VERSION ""

NS_ :

BS_:

BU_: PDM INV U2C VCU BMS Charger Can_Isolator CAN_T_Repeater CAN_Isolator

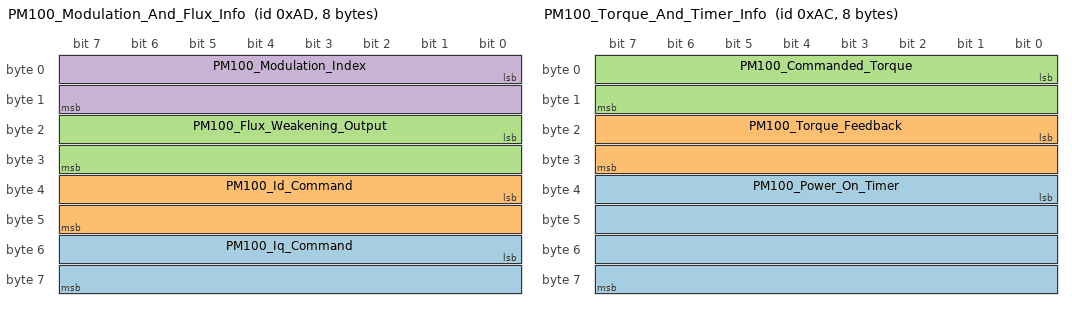
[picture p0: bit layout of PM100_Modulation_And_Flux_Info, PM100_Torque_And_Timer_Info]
BO_ 173 PM100_Modulation_And_Flux_Info: 8 INV
 SG_ PM100_Iq_Command : 48|16@1- (0.1,0) [-3276.8|3276.7] "A" Vector__XXX
 SG_ PM100_Id_Command : 32|16@1- (0.1,0) [-3276.8|3276.7] "A" Vector__XXX
 SG_ PM100_Flux_Weakening_Output : 16|16@1- (0.1,0) [-3276.8|3276.7] "A" Vector__XXX
 SG_ PM100_Modulation_Index : 0|16@1- (0.0001,0) [-3.2768|3.2767] "" Vector__XXX

BO_ 172 PM100_Torque_And_Timer_Info: 8 INV
 SG_ PM100_Power_On_Timer : 32|32@1+ (0.003,0) [0|12884800] "s" Vector__XXX
 SG_ PM100_Torque_Feedback : 16|16@1- (0.1,0) [-3276.8|3276.7] "Nm" Vector__XXX
 SG_ PM100_Commanded_Torque : 0|16@1- (0.1,0) [-3276.8|3276.7] "Nm" Vector__XXX

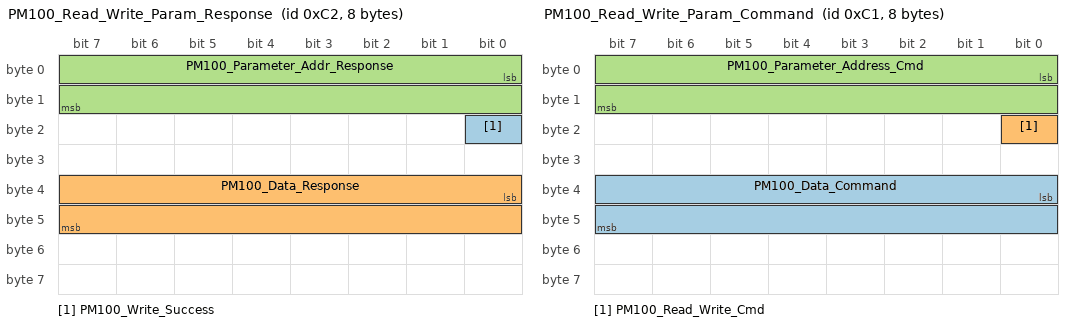
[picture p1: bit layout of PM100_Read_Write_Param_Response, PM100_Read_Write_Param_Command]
BO_ 194 PM100_Read_Write_Param_Response: 8 INV
 SG_ PM100_Write_Success : 16|1@1+ (1,0) [0|1] "" Vector__XXX
 SG_ PM100_Data_Response : 32|16@1- (1,0) [-32768|32767] "" Vector__XXX
 SG_ PM100_Parameter_Addr_Response : 0|16@1+ (1,0) [0|65535] "" Vector__XXX

BO_ 193 PM100_Read_Write_Param_Command: 8 VCU
 SG_ PM100_Data_Command : 32|16@1- (1,0) [-32768|32767] "" Vector__XXX
 SG_ PM100_Read_Write_Cmd : 16|1@1+ (1,0) [0|1] "" Vector__XXX
 SG_ PM100_Parameter_Address_Cmd : 0|16@1+ (1,0) [0|65535] "" Vector__XXX

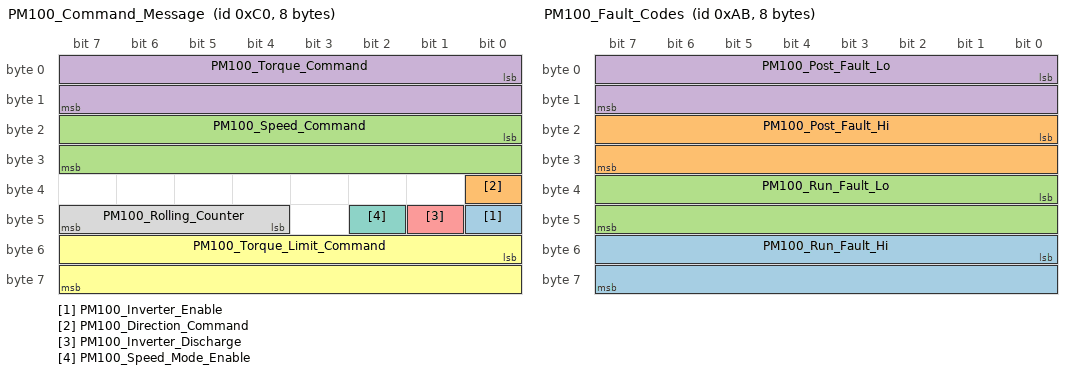
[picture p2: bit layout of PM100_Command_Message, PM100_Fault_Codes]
BO_ 192 PM100_Command_Message: 8 VCU
 SG_ PM100_Inverter_Enable : 40|1@1+ (1,0) [0|1] "Bit" Vector__XXX
 SG_ PM100_Direction_Command : 32|1@1+ (1,0) [0|1] "Bit" Vector__XXX
 SG_ PM100_Speed_Command : 16|16@1- (1,0) [-32768|32767] "rpm" Vector__XXX
 SG_ PM100_Torque_Command : 0|16@1- (0.1,0) [-3276.8|3276.7] "Nm" Vector__XXX
 SG_ PM100_Inverter_Discharge : 41|1@1+ (1,0) [0|1] "Bit" Vector__XXX
 SG_ PM100_Torque_Limit_Command : 48|16@1- (0.1,0) [-3276.8|3276.7] "Nm" Vector__XXX
 SG_ PM100_Speed_Mode_Enable : 42|1@1+ (1,0) [0|1] "Bit" Vector__XXX
 SG_ PM100_Rolling_Counter : 44|4@1+ (1,0) [0|15] "Bits" Vector__XXX

BO_ 171 PM100_Fault_Codes: 8 INV
 SG_ PM100_Run_Fault_Hi : 48|16@1+ (1,0) [0|65535] "" Vector__XXX
 SG_ PM100_Post_Fault_Hi : 16|16@1+ (1,0) [0|65535] "" Vector__XXX
 SG_ PM100_Run_Fault_Lo : 32|16@1+ (1,0) [0|65535] "" Vector__XXX
 SG_ PM100_Post_Fault_Lo : 0|16@1+ (1,0) [0|65535] "" Vector__XXX

BO_ 170 PM100_Internal_States: 8 INV
 SG_ PM100_Direction_Command : 56|1@1+ (1,0) [0|1] "" Vector__XXX
 SG_ PM100_Inverter_Enable_State : 48|1@1+ (1,0) [0|1] "" Vector__XXX
 SG_ PM100_Relay_3_Status : 26|1@1+ (1,0) [0|1] "" Vector__XXX
 SG_ PM100_Relay_4_Status : 27|1@1+ (1,0) [0|1] "" Vector__XXX
 SG_ PM100_Relay_2_Status : 25|1@1+ (1,0) [0|1] "" Vector__XXX
 SG_ PM100_Inverter_Run_Mode : 32|1@1+ (1,0) [0|1] "" Vector__XXX
 SG_ PM100_Inverter_Command_Mode : 40|1@1+ (1,0) [0|1] "" Vector__XXX
 SG_ PM100_Relay_1_Status : 24|1@1+ (1,0) [0|1] "" Vector__XXX
 SG_ PM100_Inverter_State : 16|8@1+ (1,0) [0|255] "" Vector__XXX
 SG_ PM100_VSM_State : 0|8@1+ (1,0) [0|15] "" Vector__XXX
 SG_ PM100_Inverter_Enable_Lockout : 55|1@1+ (1,0) [0|1] "" Vector__XXX
 SG_ PM100_Inverter_Discharge_State : 37|3@1+ (1,0) [0|7] "" Vector__XXX
 SG_ PM100_Relay_5_Status : 28|1@1+ (1,0) [0|1] "" Vector__XXX
 SG_ PM100_Relay_6_Status : 29|1@1+ (1,0) [0|1] "" Vector__XXX
 SG_ PM100_BMS_Active : 57|1@1+ (1,0) [0|1] "" Vector__XXX
 SG_ PM100_BMS_Torque_Limiting : 58|1@1+ (1,0) [0|1] "" Vector__XXX
 SG_ PM100_Max_Speed_Limiting : 59|1@1+ (1,0) [0|1] "" Vector__XXX
 SG_ PM100_Low_Speed_Limiting : 61|1@1+ (1,0) [0|1] "" Vector__XXX
 SG_ PM100_Rolling_Counter : 44|4@1+ (1,0) [0|15] "" Vector__XXX
 SG_ PM100_PWM_Frequency : 8|8@1+ (1,0) [0|255] "kHz" Vector__XXX
 SG_ PM100_Start_Mode_Active : 54|1@1+ (1,0) [0|1] "" Vector__XXX

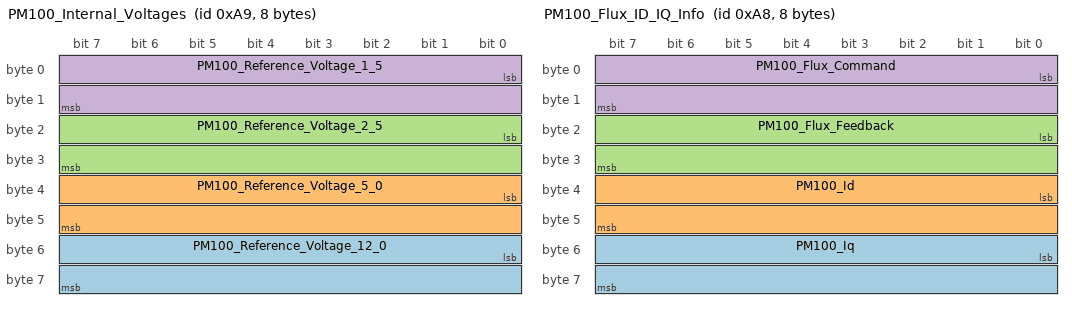
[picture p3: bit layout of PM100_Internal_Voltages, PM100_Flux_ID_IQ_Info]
BO_ 169 PM100_Internal_Voltages: 8 INV
 SG_ PM100_Reference_Voltage_12_0 : 48|16@1- (0.01,0) [-327.68|327.67] "V" Vector__XXX
 SG_ PM100_Reference_Voltage_5_0 : 32|16@1- (0.01,0) [-327.68|327.67] "V" Vector__XXX
 SG_ PM100_Reference_Voltage_2_5 : 16|16@1- (0.01,0) [-327.68|327.67] "V" Vector__XXX
 SG_ PM100_Reference_Voltage_1_5 : 0|16@1- (0.01,0) [-327.68|327.67] "V" Vector__XXX

BO_ 168 PM100_Flux_ID_IQ_Info: 8 INV
 SG_ PM100_Iq : 48|16@1- (0.1,0) [-3276.8|3276.7] "A" Vector__XXX
 SG_ PM100_Id : 32|16@1- (0.1,0) [-3276.8|3276.7] "A" Vector__XXX
 SG_ PM100_Flux_Feedback : 16|16@1- (0.001,0) [-32.768|32.767] "Wb" Vector__XXX
 SG_ PM100_Flux_Command : 0|16@1- (0.001,0) [-32.768|32.767] "Wb" Vector__XXX

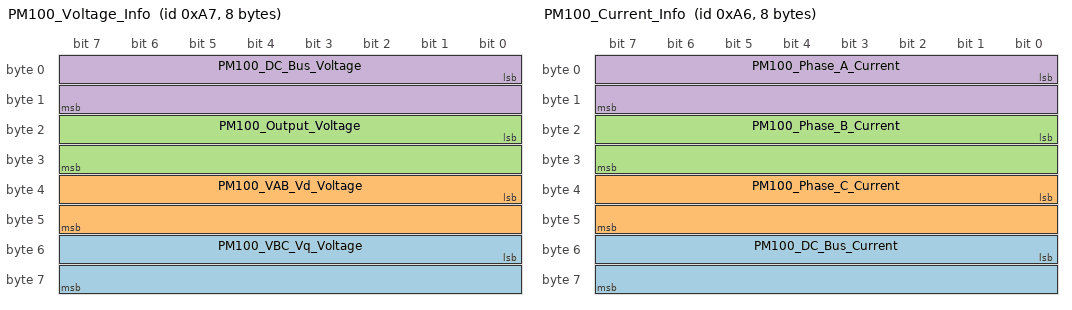
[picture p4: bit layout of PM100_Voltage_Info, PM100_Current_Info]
BO_ 167 PM100_Voltage_Info: 8 INV
 SG_ PM100_VBC_Vq_Voltage : 48|16@1- (0.1,0) [-3276.8|3276.7] "V" Vector__XXX
 SG_ PM100_VAB_Vd_Voltage : 32|16@1- (0.1,0) [-3276.8|3276.7] "V" Vector__XXX
 SG_ PM100_Output_Voltage : 16|16@1- (0.1,0) [-3276.8|3276.7] "V" Vector__XXX
 SG_ PM100_DC_Bus_Voltage : 0|16@1- (0.1,0) [-3276.8|3276.7] "V" Vector__XXX

BO_ 166 PM100_Current_Info: 8 INV
 SG_ PM100_DC_Bus_Current : 48|16@1- (0.1,0) [-3276.8|3276.7] "A" Vector__XXX
 SG_ PM100_Phase_C_Current : 32|16@1- (0.1,0) [-3276.8|3276.7] "A" Vector__XXX
 SG_ PM100_Phase_B_Current : 16|16@1- (0.1,0) [-3276.8|3276.7] "A" Vector__XXX
 SG_ PM100_Phase_A_Current : 0|16@1- (0.1,0) [-3276.8|3276.7] "A" Vector__XXX

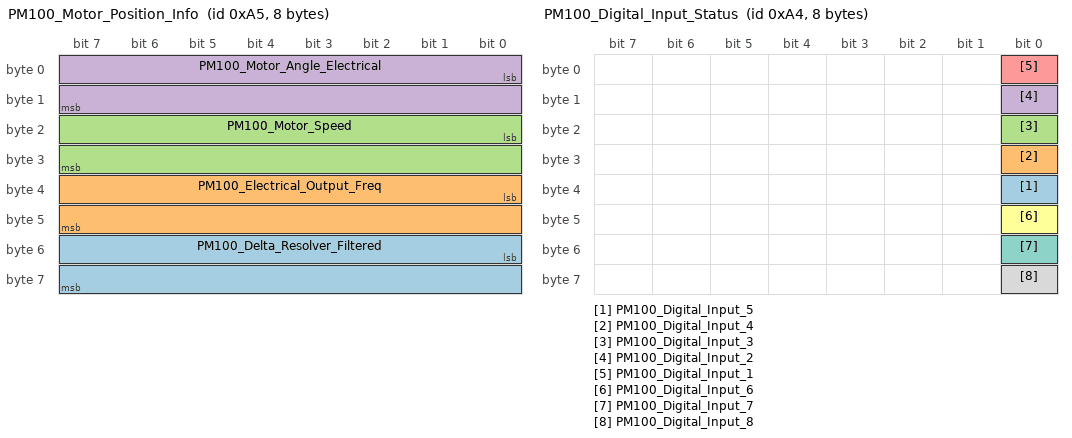
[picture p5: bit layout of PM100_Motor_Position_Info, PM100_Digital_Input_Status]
BO_ 165 PM100_Motor_Position_Info: 8 INV
 SG_ PM100_Delta_Resolver_Filtered : 48|16@1- (0.1,0) [-3276.8|3276.7] "deg" Vector__XXX
 SG_ PM100_Electrical_Output_Freq : 32|16@1- (0.1,0) [-3276.8|3276.7] "hz" Vector__XXX
 SG_ PM100_Motor_Speed : 16|16@1- (1,0) [-32768|32767] "rpm" Vector__XXX
 SG_ PM100_Motor_Angle_Electrical : 0|16@1+ (0.1,0) [0|6553.5] "deg" Vector__XXX

BO_ 164 PM100_Digital_Input_Status: 8 INV
 SG_ PM100_Digital_Input_5 : 32|1@1+ (1,0) [0|1] "boolean" Vector__XXX
 SG_ PM100_Digital_Input_4 : 24|1@1+ (1,0) [0|1] "boolean" Vector__XXX
 SG_ PM100_Digital_Input_3 : 16|1@1+ (1,0) [0|1] "boolean" Vector__XXX
 SG_ PM100_Digital_Input_2 : 8|1@1+ (1,0) [0|1] "boolean" Vector__XXX
 SG_ PM100_Digital_Input_1 : 0|1@1+ (1,0) [0|1] "boolean" Vector__XXX
 SG_ PM100_Digital_Input_6 : 40|1@1+ (1,0) [0|1] "boolean" Vector__XXX
 SG_ PM100_Digital_Input_7 : 48|1@1+ (1,0) [0|1] "boolean" Vector__XXX
 SG_ PM100_Digital_Input_8 : 56|1@1+ (1,0) [0|1] "boolean" Vector__XXX

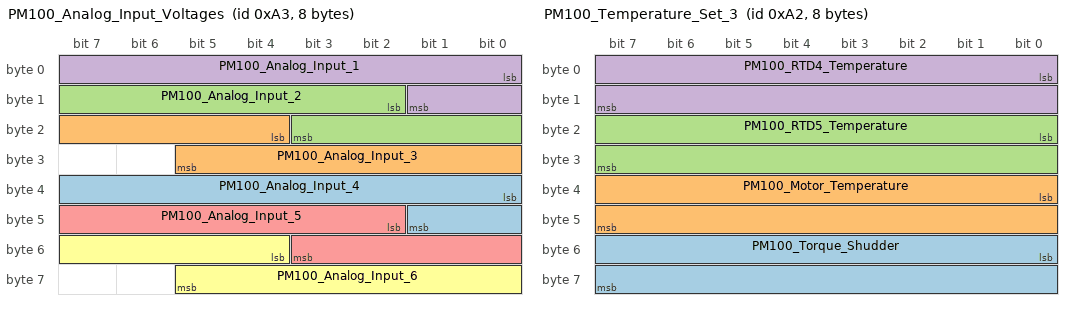
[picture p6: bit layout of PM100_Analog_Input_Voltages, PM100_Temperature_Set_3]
BO_ 163 PM100_Analog_Input_Voltages: 8 INV
 SG_ PM100_Analog_Input_4 : 32|10@1+ (0.01,0) [0|10.23] "V" Vector__XXX
 SG_ PM100_Analog_Input_3 : 20|10@1+ (0.01,0) [0|10.23] "V" Vector__XXX
 SG_ PM100_Analog_Input_2 : 10|10@1+ (0.01,0) [0|10.23] "V" Vector__XXX
 SG_ PM100_Analog_Input_1 : 0|10@1+ (0.01,0) [0|10.23] "V" Vector__XXX
 SG_ PM100_Analog_Input_5 : 42|10@1+ (0.01,0) [0|10.23] "V" Vector__XXX
 SG_ PM100_Analog_Input_6 : 52|10@1+ (0.01,0) [0|10.23] "V" Vector__XXX

BO_ 162 PM100_Temperature_Set_3: 8 INV
 SG_ PM100_Torque_Shudder : 48|16@1- (0.1,0) [-3276.8|3276.7] "Nm" Vector__XXX
 SG_ PM100_Motor_Temperature : 32|16@1- (0.1,0) [-3276.8|3276.7] "degC" Vector__XXX
 SG_ PM100_RTD5_Temperature : 16|16@1- (0.1,0) [-3276.8|3276.7] "degC" Vector__XXX
 SG_ PM100_RTD4_Temperature : 0|16@1- (0.1,0) [-3276.8|3276.7] "degC" Vector__XXX

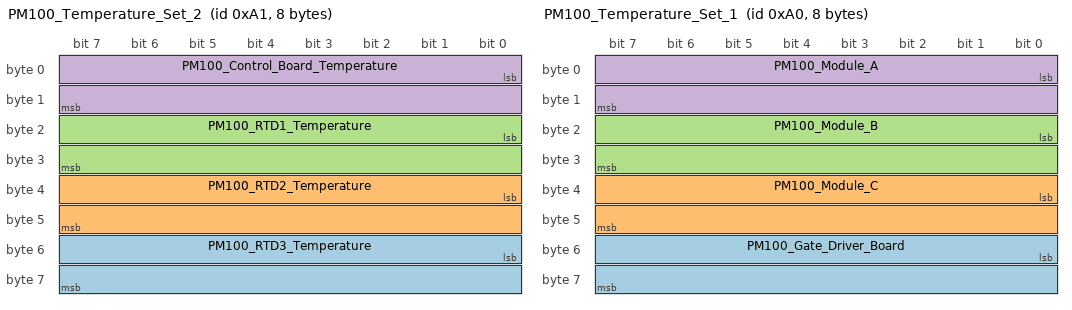
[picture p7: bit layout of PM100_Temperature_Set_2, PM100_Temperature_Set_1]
BO_ 161 PM100_Temperature_Set_2: 8 INV
 SG_ PM100_RTD3_Temperature : 48|16@1- (0.1,0) [-3276.8|3276.7] "degC" Vector__XXX
 SG_ PM100_RTD2_Temperature : 32|16@1- (0.1,0) [-3276.8|3276.7] "degC" Vector__XXX
 SG_ PM100_RTD1_Temperature : 16|16@1- (0.1,0) [-3276.8|3276.7] "degC" Vector__XXX
 SG_ PM100_Control_Board_Temperature : 0|16@1- (0.1,0) [-3276.8|3276.7] "degC" Vector__XXX

BO_ 160 PM100_Temperature_Set_1: 8 INV
 SG_ PM100_Gate_Driver_Board : 48|16@1- (0.1,0) [-3276.8|3276.7] "degC" Vector__XXX
 SG_ PM100_Module_C : 32|16@1- (0.1,0) [-3276.8|3276.7] "degC" Vector__XXX
 SG_ PM100_Module_B : 16|16@1- (0.1,0) [-3276.8|3276.7] "degC" Vector__XXX
 SG_ PM100_Module_A : 0|16@1- (0.1,0) [-3276.8|3276.7] "degC" Vector__XXX

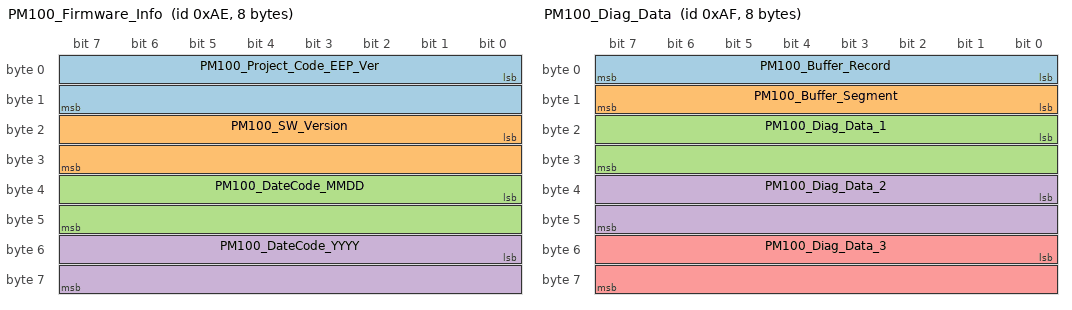
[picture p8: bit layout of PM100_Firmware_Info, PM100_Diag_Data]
BO_ 174 PM100_Firmware_Info: 8 INV
 SG_ PM100_Project_Code_EEP_Ver : 0|16@1+ (1,0) [0|65535] "" Vector__XXX
 SG_ PM100_SW_Version : 16|16@1+ (1,0) [0|65535] "" Vector__XXX
 SG_ PM100_DateCode_MMDD : 32|16@1+ (1,0) [0|65535] "" Vector__XXX
 SG_ PM100_DateCode_YYYY : 48|16@1+ (1,0) [0|65535] "" Vector__XXX

BO_ 175 PM100_Diag_Data: 8 INV
 SG_ PM100_Buffer_Record : 0|8@1+ (1,0) [0|255] "" Vector__XXX
 SG_ PM100_Buffer_Segment : 8|8@1+ (1,0) [0|5] "" Vector__XXX
 SG_ PM100_Diag_Data_1 : 16|16@1- (1,0) [-32768|32767] "" Vector__XXX
 SG_ PM100_Diag_Data_2 : 32|16@1- (1,0) [-32768|32767] "" Vector__XXX
 SG_ PM100_Diag_Data_3 : 48|16@1- (1,0) [-32768|32767] "" Vector__XXX

BO_ 471 U2C_Command_Txd: 8 INV
 SG_ PM100_ID_Byte : 0|8@1+ (1,0) [0|255] "" Vector__XXX
 SG_ PM100_Setpoint_Calc : 8|8@1+ (1,0) [0|255] "" Vector__XXX

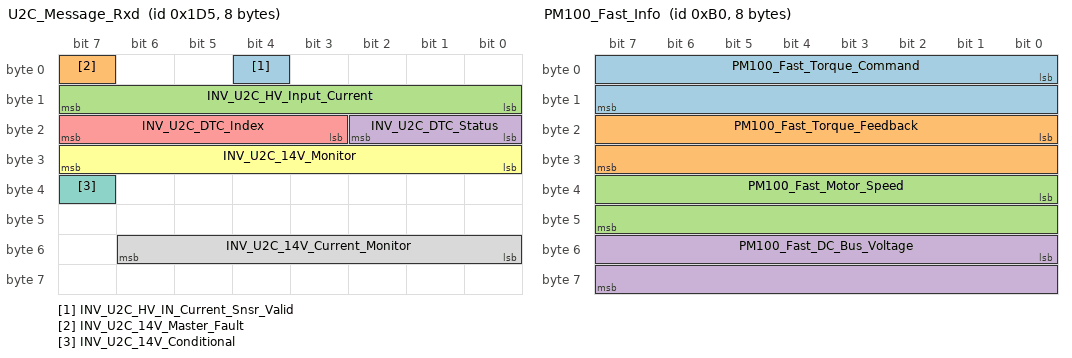
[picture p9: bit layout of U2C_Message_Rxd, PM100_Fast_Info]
BO_ 469 U2C_Message_Rxd: 8 U2C
 SG_ INV_U2C_HV_IN_Current_Snsr_Valid : 4|1@1+ (1,0) [0|1] "" Vector__XXX
 SG_ INV_U2C_14V_Master_Fault : 7|1@1+ (1,0) [0|1] "" Vector__XXX
 SG_ INV_U2C_HV_Input_Current : 8|8@1+ (1,0) [0|255] "" Vector__XXX
 SG_ INV_U2C_DTC_Status : 16|3@1+ (1,0) [0|7] "" Vector__XXX
 SG_ INV_U2C_DTC_Index : 19|5@1+ (1,0) [0|31] "" Vector__XXX
 SG_ INV_U2C_14V_Monitor : 24|8@1+ (1,0) [0|255] "" Vector__XXX
 SG_ INV_U2C_14V_Conditional : 39|1@1+ (1,0) [0|1] "" Vector__XXX
 SG_ INV_U2C_14V_Current_Monitor : 48|7@1+ (1,0) [0|127] "" Vector__XXX

BO_ 176 PM100_Fast_Info: 8 INV
 SG_ PM100_Fast_Torque_Command : 0|16@1- (0.1,0) [-3276.8|3276.7] "Nm" Vector__XXX
 SG_ PM100_Fast_Torque_Feedback : 16|16@1- (0.1,0) [-3276.8|3276.7] "Nm" Vector__XXX
 SG_ PM100_Fast_Motor_Speed : 32|16@1- (1,0) [-32768|32767] "rpm" Vector__XXX
 SG_ PM100_Fast_DC_Bus_Voltage : 48|16@1- (0.1,0) [-3276.8|3276.7] "V" Vector__XXX

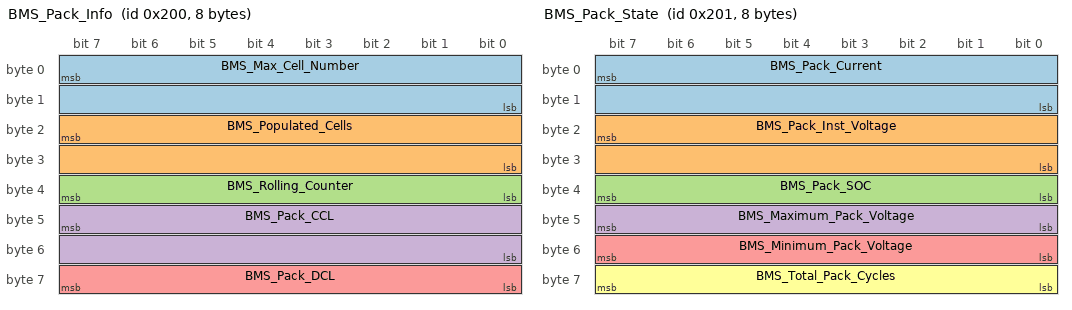
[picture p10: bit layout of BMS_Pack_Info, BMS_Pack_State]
BO_ 512 BMS_Pack_Info: 8 BMS
 SG_ BMS_Max_Cell_Number : 7|16@0+ (1,0) [0|0] "Num" Vector__XXX
 SG_ BMS_Populated_Cells : 23|16@0+ (1,0) [0|0] "Num" Vector__XXX
 SG_ BMS_Rolling_Counter : 39|8@0+ (1,0) [0|0] "Num" Vector__XXX
 SG_ BMS_Pack_CCL : 47|16@0+ (1,0) [0|0] "Amps" Vector__XXX
 SG_ BMS_Pack_DCL : 63|8@0+ (1,1720) [0|0] "Amps" Vector__XXX

BO_ 513 BMS_Pack_State: 8 BMS
 SG_ BMS_Pack_Current : 7|16@0- (0.1,0) [0|0] "Amps" Vector__XXX
 SG_ BMS_Pack_Inst_Voltage : 23|16@0+ (0.1,0) [0|0] "Volts" Vector__XXX
 SG_ BMS_Pack_SOC : 39|8@0+ (0.5,0) [0|0] "Percent" Vector__XXX
 SG_ BMS_Maximum_Pack_Voltage : 47|8@0+ (0.1,0) [0|0] "Volts" Vector__XXX
 SG_ BMS_Minimum_Pack_Voltage : 55|8@0+ (0.1,0) [0|0] "Volts" Vector__XXX
 SG_ BMS_Total_Pack_Cycles : 63|8@0+ (1,1721) [0|0] "Num" Vector__XXX

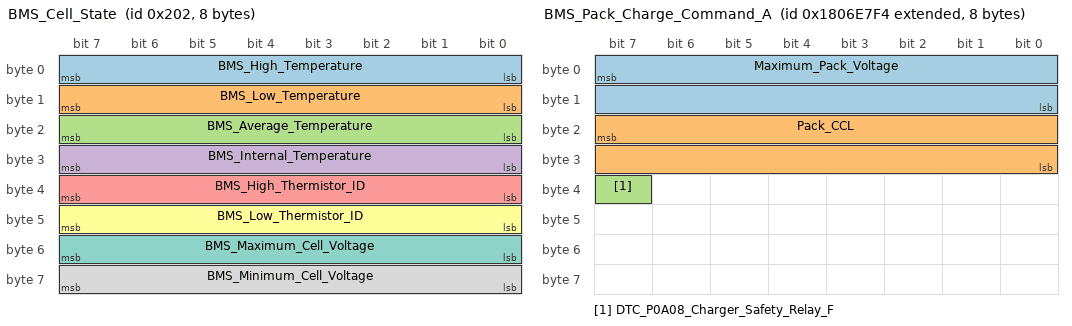
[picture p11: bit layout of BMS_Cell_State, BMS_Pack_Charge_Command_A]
BO_ 514 BMS_Cell_State: 8 BMS
 SG_ BMS_High_Temperature : 7|8@0+ (1,0) [0|0] "Celsius" Vector__XXX
 SG_ BMS_Low_Temperature : 15|8@0+ (1,0) [0|0] "Celsius" Vector__XXX
 SG_ BMS_Average_Temperature : 23|8@0+ (1,0) [0|0] "Celsius" Vector__XXX
 SG_ BMS_Internal_Temperature : 31|8@0+ (1,0) [0|0] "Celsius" Vector__XXX
 SG_ BMS_High_Thermistor_ID : 39|8@0+ (1,0) [0|0] "ID" Vector__XXX
 SG_ BMS_Low_Thermistor_ID : 47|8@0+ (1,0) [0|0] "ID" Vector__XXX
 SG_ BMS_Maximum_Cell_Voltage : 55|8@0+ (0.0001,0) [0|0] "Volts" Vector__XXX
 SG_ BMS_Minimum_Cell_Voltage : 63|8@0+ (0.0001,0) [0|0] "Volts" Vector__XXX

BO_ 515 BMS_Status: 7 BMS
 SG_ BMS_High_Cell_Voltage_ID : 0|8@1+ (1,0) [0|0] "ID" Vector__XXX
 SG_ BMS_Low_Cell_Voltage_ID : 8|8@1+ (1,0) [0|0] "ID" Vector__XXX
 SG_ BMS_Discharge_Relay : 16|1@1+ (1,0) [0|1] "" Vector__XXX
 SG_ BMS_Charge_Relay : 17|1@1+ (1,0) [0|1] "" Vector__XXX
 SG_ BMS_Charger_Safety : 18|1@1+ (1,0) [0|1] "" Vector__XXX
 SG_ BMS_Charge_Interlock : 19|1@1+ (1,0) [0|1] "" Vector__XXX
 SG_ BMS_Balancing_Active : 20|1@1+ (1,0) [0|1] "" Vector__XXX
 SG_ BMS_FAULT_Int_Cell_Comms : 24|1@1+ (1,0) [0|1] "" Vector__XXX
 SG_ BMS_FAULT_Cell_Bal_Stuck_Off : 25|1@1+ (1,0) [0|1] "" Vector__XXX
 SG_ BMS_FAULT_Weak_Cell : 26|1@1+ (1,0) [0|1] "" Vector__XXX
 SG_ BMS_FAULT_Low_Cell_Voltage : 27|1@1+ (1,0) [0|1] "" Vector__XXX
 SG_ BMS_FAULT_Cell_Open_Wiring : 28|1@1+ (1,0) [0|1] "" Vector__XXX
 SG_ BMS_FAULT_Current_Sensor : 29|1@1+ (1,0) [0|1] "" Vector__XXX
 SG_ BMS_FAULT_Cell_Voltage_Over_5V : 30|1@1+ (1,0) [0|1] "" Vector__XXX
 SG_ BMS_FAULT_Cell_Bank : 31|1@1+ (1,0) [0|1] "" Vector__XXX
 SG_ BMS_FAULT_Weak_Pack : 32|1@1+ (1,0) [0|1] "" Vector__XXX
 SG_ BMS_FAULT_Fan_Monitor : 33|1@1+ (1,0) [0|1] "" Vector__XXX
 SG_ BMS_FAULT_Thermistor : 34|1@1+ (1,0) [0|1] "" Vector__XXX
 SG_ BMS_FAULT_CAN_Communication : 35|1@1+ (1,0) [0|1] "" Vector__XXX
 SG_ BMS_FAULT_Redundant_Power_Supply : 36|1@1+ (1,0) [0|1] "" Vector__XXX
 SG_ BMS_FAULT_High_Voltage_Isolation : 37|1@1+ (1,0) [0|1] "" Vector__XXX
 SG_ BMS_FAULT_Invld_Input_Sply_Volt : 38|1@1+ (1,0) [0|1] "" Vector__XXX
 SG_ BMS_FAULT_ChargeEnable_Relay : 39|1@1+ (1,0) [0|1] "" Vector__XXX
 SG_ BMS_FAULT_DischargeEnable_Relay : 40|1@1+ (1,0) [0|1] "" Vector__XXX
 SG_ BMS_FAULT_Charger_Safety_Relay : 41|1@1+ (1,0) [0|1] "" Vector__XXX
 SG_ BMS_FAULT_Internal_Hardware : 42|1@1+ (1,0) [0|1] "" Vector__XXX
 SG_ BMS_FAULT_Internal_Temp : 43|1@1+ (1,0) [0|1] "" Vector__XXX
 SG_ BMS_FAULT_Internal_Logic : 44|1@1+ (1,0) [0|1] "" Vector__XXX
 SG_ BMS_FAULT_Hi_Cell_Voltage_High : 45|1@1+ (1,0) [0|1] "" Vector__XXX
 SG_ BMS_FAULT_Lo_Cell_Voltage_Low : 46|1@1+ (1,0) [0|1] "" Vector__XXX
 SG_ BMS_FAULT_Pack_Too_Hot : 47|1@1+ (1,0) [0|1] "" Vector__XXX
 SG_ BMS_FAULT_Hi_Volt_Intlck_Signal : 48|1@1+ (1,0) [0|1] "" Vector__XXX
 SG_ BMS_FAULT_Prchrg_Malfunction : 49|1@1+ (1,0) [0|1] "" Vector__XXX
 SG_ BMS_FAULT_Abnormal_SoC_Behavior : 50|1@1+ (1,0) [0|1] "" Vector__XXX

BO_ 528 BMS_Heartbeat: 8 Can_Isolator

BO_ 2550589428 BMS_Pack_Charge_Command_A: 8 BMS
 SG_ Maximum_Pack_Voltage : 7|16@0+ (0.1,0) [0|0] "Volts"  Charger
 SG_ Pack_CCL : 23|16@0+ (0.1,0) [0|0] "Amps"  Charger
 SG_ DTC_P0A08_Charger_Safety_Relay_F : 39|1@1+ (1,0) [0|1] ""  Charger

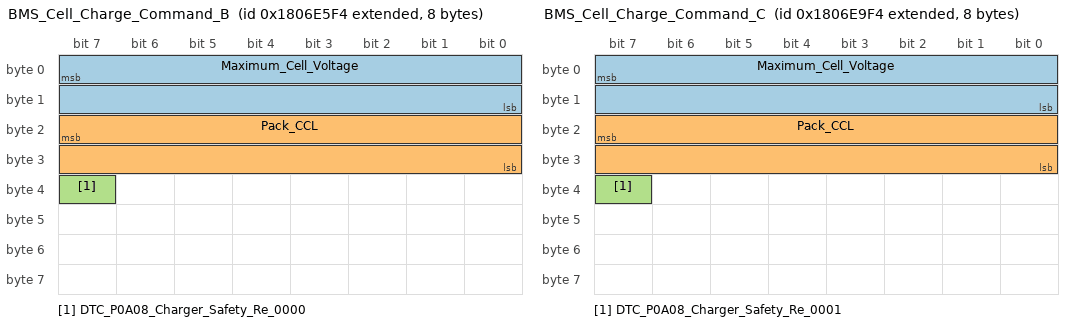
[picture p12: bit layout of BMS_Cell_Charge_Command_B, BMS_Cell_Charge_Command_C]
BO_ 2550588916 BMS_Cell_Charge_Command_B: 8 BMS
 SG_ Maximum_Cell_Voltage : 7|16@0+ (0.00104166666666667,0) [0|0] "Volts"  Charger
 SG_ Pack_CCL : 23|16@0+ (0.1,0) [0|0] "Amps"  Charger
 SG_ DTC_P0A08_Charger_Safety_Re_0000 : 39|1@1+ (1,0) [0|1] ""  Charger

BO_ 2550589940 BMS_Cell_Charge_Command_C: 8 BMS
 SG_ Maximum_Cell_Voltage : 7|16@0+ (0.00104166666666667,0) [0|0] "Volts"  Charger
 SG_ Pack_CCL : 23|16@0+ (0.1,0) [0|0] "Amps"  Charger
 SG_ DTC_P0A08_Charger_Safety_Re_0001 : 39|1@1+ (1,0) [0|1] ""  Charger

BO_ 118 BMS_Fast_Thermistor_Broadcast: 4 BMS
 SG_ BMS_Fast_Thermistor_ID M : 0|8@1+ (1,0) [0|255] "ID" Vector__XXX
 SG_ BMS_Fast_Temp_0 m0 : 8|8@1- (1,0) [-128|127] "C" Vector__XXX
 SG_ BMS_Fast_Fault_0 m0 : 16|8@1+ (1,0) [0|1] "Bool" Vector__XXX
 SG_ BMS_Fast_Temp_1 m1 : 8|8@1- (1,0) [-128|127] "C" Vector__XXX
 SG_ BMS_Fast_Fault_1 m1 : 16|8@1+ (1,0) [0|1] "Bool" Vector__XXX
 SG_ BMS_Fast_Temp_2 m2 : 8|8@1- (1,0) [-128|127] "C" Vector__XXX
 SG_ BMS_Fast_Fault_2 m2 : 16|8@1+ (1,0) [0|1] "Bool" Vector__XXX
 SG_ BMS_Fast_Temp_3 m3 : 8|8@1- (1,0) [-128|127] "C" Vector__XXX
 SG_ BMS_Fast_Fault_3 m3 : 16|8@1+ (1,0) [0|1] "Bool" Vector__XXX
 SG_ BMS_Fast_Temp_4 m4 : 8|8@1- (1,0) [-128|127] "C" Vector__XXX
 SG_ BMS_Fast_Fault_4 m4 : 16|8@1+ (1,0) [0|1] "Bool" Vector__XXX
 SG_ BMS_Fast_Temp_5 m5 : 8|8@1- (1,0) [-128|127] "C" Vector__XXX
 SG_ BMS_Fast_Fault_5 m5 : 16|8@1+ (1,0) [0|1] "Bool" Vector__XXX
 SG_ BMS_Fast_Temp_6 m6 : 8|8@1- (1,0) [-128|127] "C" Vector__XXX
 SG_ BMS_Fast_Fault_6 m6 : 16|8@1+ (1,0) [0|1] "Bool" Vector__XXX
 SG_ BMS_Fast_Temp_7 m7 : 8|8@1- (1,0) [-128|127] "C" Vector__XXX
 SG_ BMS_Fast_Fault_7 m7 : 16|8@1+ (1,0) [0|1] "Bool" Vector__XXX

BO_ 2566869221 Charger_Heartbeat: 8 Charger

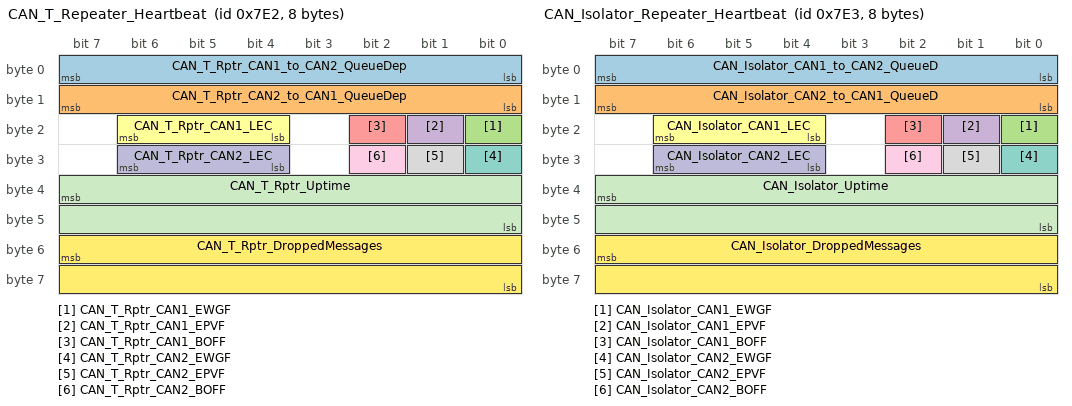
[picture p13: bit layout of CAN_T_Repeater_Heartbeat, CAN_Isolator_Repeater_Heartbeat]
BO_ 2018 CAN_T_Repeater_Heartbeat: 8 CAN_T_Repeater
 SG_ CAN_T_Rptr_CAN1_to_CAN2_QueueDep : 0|8@1+ (1,0) [0|255] "msgs" Vector__XXX
 SG_ CAN_T_Rptr_CAN2_to_CAN1_QueueDep : 8|8@1+ (1,0) [0|255] "msgs" Vector__XXX
 SG_ CAN_T_Rptr_CAN1_EWGF : 16|1@1+ (1,0) [0|1] "" Vector__XXX
 SG_ CAN_T_Rptr_CAN1_EPVF : 17|1@1+ (1,0) [0|1] "" Vector__XXX
 SG_ CAN_T_Rptr_CAN1_BOFF : 18|1@1+ (1,0) [0|1] "" Vector__XXX
 SG_ CAN_T_Rptr_CAN1_LEC : 20|3@1+ (1,0) [0|7] "" Vector__XXX
 SG_ CAN_T_Rptr_CAN2_EWGF : 24|1@1+ (1,0) [0|1] "" Vector__XXX
 SG_ CAN_T_Rptr_CAN2_EPVF : 25|1@1+ (1,0) [0|1] "" Vector__XXX
 SG_ CAN_T_Rptr_CAN2_BOFF : 26|1@1+ (1,0) [0|1] "" Vector__XXX
 SG_ CAN_T_Rptr_CAN2_LEC : 28|3@1+ (1,0) [0|7] "" Vector__XXX
 SG_ CAN_T_Rptr_Uptime : 39|16@0+ (1,0) [0|65535] "s" Vector__XXX
 SG_ CAN_T_Rptr_DroppedMessages : 55|16@0+ (1,0) [0|65535] "msgs" Vector__XXX

BO_ 2019 CAN_Isolator_Repeater_Heartbeat: 8 CAN_Isolator
 SG_ CAN_Isolator_CAN1_to_CAN2_QueueD : 0|8@1+ (1,0) [0|255] "msgs" Vector__XXX
 SG_ CAN_Isolator_CAN2_to_CAN1_QueueD : 8|8@1+ (1,0) [0|255] "msgs" Vector__XXX
 SG_ CAN_Isolator_CAN1_EWGF : 16|1@1+ (1,0) [0|1] "" Vector__XXX
 SG_ CAN_Isolator_CAN1_EPVF : 17|1@1+ (1,0) [0|1] "" Vector__XXX
 SG_ CAN_Isolator_CAN1_BOFF : 18|1@1+ (1,0) [0|1] "" Vector__XXX
 SG_ CAN_Isolator_CAN1_LEC : 20|3@1+ (1,0) [0|7] "" Vector__XXX
 SG_ CAN_Isolator_CAN2_EWGF : 24|1@1+ (1,0) [0|1] "" Vector__XXX
 SG_ CAN_Isolator_CAN2_EPVF : 25|1@1+ (1,0) [0|1] "" Vector__XXX
 SG_ CAN_Isolator_CAN2_BOFF : 26|1@1+ (1,0) [0|1] "" Vector__XXX
 SG_ CAN_Isolator_CAN2_LEC : 28|3@1+ (1,0) [0|7] "" Vector__XXX
 SG_ CAN_Isolator_Uptime : 39|16@0+ (1,0) [0|65535] "s" Vector__XXX
 SG_ CAN_Isolator_DroppedMessages : 55|16@0+ (1,0) [0|65535] "msgs" Vector__XXX

BO_ 1285 PDM_In_Voltage: 8 Vector__XXX
 SG_ PDM_Serial_Number_L m4 : 56|8@1+ (1,0) [0|255] "V" Vector__XXX
 SG_ PDM_Serial_Number_H m4 : 48|8@1+ (1,0) [0|255] "V" Vector__XXX
 SG_ PDM_Firmware_Version_Minor m4 : 16|8@1+ (1,0) [0|255] "V" Vector__XXX
 SG_ PDM_Firmware_Version_Major m4 : 8|8@1+ (1,0) [0|255] "V" Vector__XXX
 SG_ PDM_Firmware_Version_Letter m4 : 24|8@1+ (1,0) [0|255] "V" Vector__XXX
 SG_ PDM_Input_9_Voltage m1 : 16|8@1+ (0.2,0) [0|51] "V" Vector__XXX
 SG_ PDM_Input_8_Voltage m1 : 8|8@1+ (0.2,0) [0|51] "V" Vector__XXX
 SG_ PDM_Input_7_Voltage m0 : 56|8@1+ (0.2,0) [0|51] "V" Vector__XXX
 SG_ PDM_Input_6_Voltage m0 : 48|8@1+ (0.2,0) [0|51] "V" Vector__XXX
 SG_ PDM_Input_5_Voltage m0 : 40|8@1+ (0.2,0) [0|51] "V" Vector__XXX
 SG_ PDM_Input_4_Voltage m0 : 32|8@1+ (0.2,0) [0|51] "V" Vector__XXX
 SG_ PDM_Input_3_Voltage m0 : 24|8@1+ (0.2,0) [0|51] "V" Vector__XXX
 SG_ PDM_Input_2_Voltage m0 : 16|8@1+ (0.2,0) [0|51] "V" Vector__XXX
 SG_ PDM_Input_23_Voltage m3 : 16|8@1+ (0.2,0) [0|51] "V" Vector__XXX
 SG_ PDM_Input_22_Voltage m3 : 8|8@1+ (0.2,0) [0|51] "V" Vector__XXX
 SG_ PDM_Input_21_Voltage m2 : 56|8@1+ (0.2,0) [0|51] "V" Vector__XXX
 SG_ PDM_Input_20_Voltage m2 : 48|8@1+ (0.2,0) [0|51] "V" Vector__XXX
 SG_ PDM_Input_19_Voltage m2 : 40|8@1+ (0.2,0) [0|51] "V" Vector__XXX
 SG_ PDM_Input_18_Voltage m2 : 32|8@1+ (0.2,0) [0|51] "V" Vector__XXX
 SG_ PDM_Input_17_Voltage m2 : 24|8@1+ (0.2,0) [0|51] "V" Vector__XXX
 SG_ PDM_Input_16_Voltage m2 : 16|8@1+ (0.2,0) [0|51] "V" Vector__XXX
 SG_ PDM_Input_15_Voltage m2 : 8|8@1+ (0.2,0) [0|51] "V" Vector__XXX
 SG_ PDM_Input_14_Voltage m1 : 56|8@1+ (0.2,0) [0|51] "V" Vector__XXX
 SG_ PDM_Input_13_Voltage m1 : 48|8@1+ (0.2,0) [0|51] "V" Vector__XXX
 SG_ PDM_Input_12_Voltage m1 : 40|8@1+ (0.2,0) [0|51] "V" Vector__XXX
 SG_ PDM_Input_11_Voltage m1 : 32|8@1+ (0.2,0) [0|51] "V" Vector__XXX
 SG_ PDM_Input_10_Voltage m1 : 24|8@1+ (0.2,0) [0|51] "V" Vector__XXX
 SG_ PDM_Input_1_Voltage m0 : 8|8@1+ (0.2,0) [0|51] "V" Vector__XXX
 SG_ PDM_In_Voltage_Compound_ID M : 0|8@1- (1,0) [0|0] "" Vector__XXX

BO_ 1284 PDM_Out_Status: 8 Vector__XXX
 SG_ PDM_Output_9_Status m1 : 0|6@1+ (1,0) [0|63] "Off/On" Vector__XXX
 SG_ PDM_Output_8_Status m0 : 56|8@1+ (1,0) [0|255] "Off/On" Vector__XXX
 SG_ PDM_Output_7_Status m0 : 48|8@1+ (1,0) [0|255] "Off/On" Vector__XXX
 SG_ PDM_Output_6_Status m0 : 40|8@1+ (1,0) [0|255] "Off/On" Vector__XXX
 SG_ PDM_Output_5_Status m0 : 32|8@1+ (1,0) [0|255] "Off/On" Vector__XXX
 SG_ PDM_Output_4_Status m0 : 24|8@1+ (1,0) [0|255] "Off/On" Vector__XXX
 SG_ PDM_Output_3_Status m0 : 16|8@1+ (1,0) [0|255] "Off/On" Vector__XXX
 SG_ PDM_Output_32_Status m3 : 56|8@1+ (1,0) [0|255] "Off/On" Vector__XXX
 SG_ PDM_Output_31_Status m3 : 48|8@1+ (1,0) [0|255] "Off/On" Vector__XXX
 SG_ PDM_Output_30_Status m3 : 40|8@1+ (1,0) [0|255] "Off/On" Vector__XXX
 SG_ PDM_Output_2_Status m0 : 8|8@1+ (1,0) [0|255] "Off/On" Vector__XXX
 SG_ PDM_Output_29_Status m3 : 32|8@1+ (1,0) [0|255] "Off/On" Vector__XXX
 SG_ PDM_Output_28_Status m3 : 24|8@1+ (1,0) [0|255] "Off/On" Vector__XXX
 SG_ PDM_Output_27_Status m3 : 16|8@1+ (1,0) [0|255] "Off/On" Vector__XXX
 SG_ PDM_Output_26_Status m3 : 8|8@1+ (1,0) [0|255] "Off/On" Vector__XXX
 SG_ PDM_Output_25_Status m3 : 0|6@1+ (1,0) [0|63] "Off/On" Vector__XXX
 SG_ PDM_Output_24_Status m2 : 56|8@1+ (1,0) [0|255] "Off/On" Vector__XXX
 SG_ PDM_Output_23_Status m2 : 48|8@1+ (1,0) [0|255] "Off/On" Vector__XXX
 SG_ PDM_Output_22_Status m2 : 40|8@1+ (1,0) [0|255] "Off/On" Vector__XXX
 SG_ PDM_Output_21_Status m2 : 32|8@1+ (1,0) [0|255] "Off/On" Vector__XXX
 SG_ PDM_Output_20_Status m2 : 24|8@1+ (1,0) [0|255] "Off/On" Vector__XXX
 SG_ PDM_Output_19_Status m2 : 16|8@1+ (1,0) [0|255] "Off/On" Vector__XXX
 SG_ PDM_Output_18_Status m2 : 8|8@1+ (1,0) [0|255] "Off/On" Vector__XXX
 SG_ PDM_Output_17_Status m2 : 0|6@1+ (1,0) [0|63] "Off/On" Vector__XXX
 SG_ PDM_Output_16_Status m1 : 56|8@1+ (1,0) [0|255] "Off/On" Vector__XXX
 SG_ PDM_Output_15_Status m1 : 48|8@1+ (1,0) [0|255] "Off/On" Vector__XXX
 SG_ PDM_Output_14_Status m1 : 40|8@1+ (1,0) [0|255] "Off/On" Vector__XXX
 SG_ PDM_Output_13_Status m1 : 32|8@1+ (1,0) [0|255] "Off/On" Vector__XXX
 SG_ PDM_Output_12_Status m1 : 24|8@1+ (1,0) [0|255] "Off/On" Vector__XXX
 SG_ PDM_Output_11_Status m1 : 16|8@1+ (1,0) [0|255] "Off/On" Vector__XXX
 SG_ PDM_Output_10_Status m1 : 8|8@1+ (1,0) [0|255] "Off/On" Vector__XXX
 SG_ PDM_Output_1_Status m0 : 0|6@1+ (1,0) [0|63] "Off/On" Vector__XXX
 SG_ PDM_Out_Status_Compound_ID M : 6|2@1- (1,0) [0|0] "Off/On" Vector__XXX

BO_ 1283 PDM_Out_Voltage: 8 Vector__XXX
 SG_ PDM_Output_9_Voltage m1 : 16|8@1+ (0.2,0) [0|51] "V" Vector__XXX
 SG_ PDM_Output_8_Voltage m1 : 8|8@1+ (0.2,0) [0|51] "V" Vector__XXX
 SG_ PDM_Output_7_Voltage m0 : 56|8@1+ (0.2,0) [0|51] "V" Vector__XXX
 SG_ PDM_Output_6_Voltage m0 : 48|8@1+ (0.2,0) [0|51] "V" Vector__XXX
 SG_ PDM_Output_5_Voltage m0 : 40|8@1+ (0.2,0) [0|51] "V" Vector__XXX
 SG_ PDM_Output_4_Voltage m0 : 32|8@1+ (0.2,0) [0|51] "V" Vector__XXX
 SG_ PDM_Output_3_Voltage m0 : 24|8@1+ (0.2,0) [0|51] "V" Vector__XXX
 SG_ PDM_Output_32_Voltage m4 : 32|8@1+ (0.2,0) [0|51] "V" Vector__XXX
 SG_ PDM_Output_31_Voltage m4 : 24|8@1+ (0.2,0) [0|51] "V" Vector__XXX
 SG_ PDM_Output_30_Voltage m4 : 16|8@1+ (0.2,0) [0|51] "V" Vector__XXX
 SG_ PDM_Output_2_Voltage m0 : 16|8@1+ (0.2,0) [0|51] "V" Vector__XXX
 SG_ PDM_Output_29_Voltage m4 : 8|8@1+ (0.2,0) [0|51] "V" Vector__XXX
 SG_ PDM_Output_28_Voltage m3 : 56|8@1+ (0.2,0) [0|51] "V" Vector__XXX
 SG_ PDM_Output_27_Voltage m3 : 48|8@1+ (0.2,0) [0|51] "V" Vector__XXX
 SG_ PDM_Output_26_Voltage m3 : 40|8@1+ (0.2,0) [0|51] "V" Vector__XXX
 SG_ PDM_Output_25_Voltage m3 : 32|8@1+ (0.2,0) [0|51] "V" Vector__XXX
 SG_ PDM_Output_24_Voltage m3 : 24|8@1+ (0.2,0) [0|51] "V" Vector__XXX
 SG_ PDM_Output_23_Voltage m3 : 16|8@1+ (0.2,0) [0|51] "V" Vector__XXX
 SG_ PDM_Output_22_Voltage m3 : 8|8@1+ (0.2,0) [0|51] "V" Vector__XXX
 SG_ PDM_Output_21_Voltage m2 : 56|8@1+ (0.2,0) [0|51] "V" Vector__XXX
 SG_ PDM_Output_20_Voltage m2 : 48|8@1+ (0.2,0) [0|51] "V" Vector__XXX
 SG_ PDM_Output_1_Voltage m0 : 8|8@1+ (0.2,0) [0|51] "V" Vector__XXX
 SG_ PDM_Output_19_Voltage m2 : 40|8@1+ (0.2,0) [0|51] "V" Vector__XXX
 SG_ PDM_Output_18_Voltage m2 : 32|8@1+ (0.2,0) [0|51] "V" Vector__XXX
 SG_ PDM_Output_17_Voltage m2 : 24|8@1+ (0.2,0) [0|51] "V" Vector__XXX
 SG_ PDM_Output_16_Voltage m2 : 16|8@1+ (0.2,0) [0|51] "V" Vector__XXX
 SG_ PDM_Output_15_Voltage m2 : 8|8@1+ (0.2,0) [0|51] "V" Vector__XXX
 SG_ PDM_Output_14_Voltage m1 : 56|8@1+ (0.2,0) [0|51] "V" Vector__XXX
 SG_ PDM_Output_13_Voltage m1 : 48|8@1+ (0.2,0) [0|51] "V" Vector__XXX
 SG_ PDM_Output_12_Voltage m1 : 40|8@1+ (0.2,0) [0|51] "V" Vector__XXX
 SG_ PDM_Output_11_Voltage m1 : 32|8@1+ (0.2,0) [0|51] "V" Vector__XXX
 SG_ PDM_Output_10_Voltage m1 : 24|8@1+ (0.2,0) [0|51] "V" Vector__XXX
 SG_ PDM_Out_Voltage_Compound_ID M : 0|8@1- (1,0) [0|0] "V" Vector__XXX

BO_ 1282 PDM_Out_Load: 8 Vector__XXX
 SG_ PDM_Output_9_Load m1 : 16|8@1+ (1,0) [0|255] "%" Vector__XXX
 SG_ PDM_Output_8_Load m1 : 8|8@1+ (1,0) [0|255] "%" Vector__XXX
 SG_ PDM_Output_7_Load m0 : 56|8@1+ (1,0) [0|255] "%" Vector__XXX
 SG_ PDM_Output_6_Load m0 : 48|8@1+ (1,0) [0|255] "%" Vector__XXX
 SG_ PDM_Output_5_Load m0 : 40|8@1+ (1,0) [0|255] "%" Vector__XXX
 SG_ PDM_Output_4_Load m0 : 32|8@1+ (1,0) [0|255] "%" Vector__XXX
 SG_ PDM_Output_3_Load m0 : 24|8@1+ (1,0) [0|255] "%" Vector__XXX
 SG_ PDM_Output_32_Load m4 : 32|8@1+ (1,0) [0|255] "%" Vector__XXX
 SG_ PDM_Output_31_Load m4 : 24|8@1+ (1,0) [0|255] "%" Vector__XXX
 SG_ PDM_Output_30_Load m4 : 16|8@1+ (1,0) [0|255] "%" Vector__XXX
 SG_ PDM_Output_2_Load m0 : 16|8@1+ (1,0) [0|255] "%" Vector__XXX
 SG_ PDM_Output_29_Load m4 : 8|8@1+ (1,0) [0|255] "%" Vector__XXX
 SG_ PDM_Output_28_Load m3 : 56|8@1+ (1,0) [0|255] "%" Vector__XXX
 SG_ PDM_Output_27_Load m3 : 48|8@1+ (1,0) [0|255] "%" Vector__XXX
 SG_ PDM_Output_26_Load m3 : 40|8@1+ (1,0) [0|255] "%" Vector__XXX
 SG_ PDM_Output_25_Load m3 : 32|8@1+ (1,0) [0|255] "%" Vector__XXX
 SG_ PDM_Output_24_Load m3 : 24|8@1+ (1,0) [0|255] "%" Vector__XXX
 SG_ PDM_Output_23_Load m3 : 16|8@1+ (1,0) [0|255] "%" Vector__XXX
 SG_ PDM_Output_22_Load m3 : 8|8@1+ (1,0) [0|255] "%" Vector__XXX
 SG_ PDM_Output_21_Load m2 : 56|8@1+ (1,0) [0|255] "%" Vector__XXX
 SG_ PDM_Output_20_Load m2 : 48|8@1+ (1,0) [0|255] "%" Vector__XXX
 SG_ PDM_Output_19_Load m2 : 40|8@1+ (1,0) [0|255] "%" Vector__XXX
 SG_ PDM_Output_18_Load m2 : 32|8@1+ (1,0) [0|255] "%" Vector__XXX
 SG_ PDM_Output_17_Load m2 : 24|8@1+ (1,0) [0|255] "%" Vector__XXX
 SG_ PDM_Output_16_Load m2 : 16|8@1+ (1,0) [0|255] "%" Vector__XXX
 SG_ PDM_Output_15_Load m2 : 8|8@1+ (1,0) [0|255] "%" Vector__XXX
 SG_ PDM_Output_14_Load m1 : 56|8@1+ (1,0) [0|255] "%" Vector__XXX
 SG_ PDM_Output_13_Load m1 : 48|8@1+ (1,0) [0|255] "%" Vector__XXX
 SG_ PDM_Output_12_Load m1 : 40|8@1+ (1,0) [0|255] "%" Vector__XXX
 SG_ PDM_Output_11_Load m1 : 32|8@1+ (1,0) [0|255] "%" Vector__XXX
 SG_ PDM_Output_10_Load m1 : 24|8@1+ (1,0) [0|255] "%" Vector__XXX
 SG_ PDM_Output_1_Load m0 : 8|8@1+ (1,0) [0|255] "%" Vector__XXX
 SG_ PDM_Out_Load_Compound_ID M : 0|8@1- (1,0) [0|240] "" Vector__XXX

BO_ 1281 PDM_Out_Current: 8 Vector__XXX
 SG_ PDM_Output_8_Current m1 : 8|8@1+ (0.5,0) [0|127.5] "A" Vector__XXX
 SG_ PDM_Output_7_Current m0 : 56|8@1+ (0.5,0) [0|127.5] "A" Vector__XXX
 SG_ PDM_Output_6_Current m0 : 48|8@1+ (0.5,0) [0|127.5] "A" Vector__XXX
 SG_ PDM_Output_5_Current m0 : 40|8@1+ (0.5,0) [0|127.5] "A" Vector__XXX
 SG_ PDM_Output_4_Current m0 : 32|8@1+ (0.5,0) [0|127.5] "A" Vector__XXX
 SG_ PDM_Output_3_Current m0 : 24|8@1+ (0.5,0) [0|127.5] "A" Vector__XXX
 SG_ PDM_Output_2_Current m0 : 16|8@1+ (0.5,0) [0|127.5] "A" Vector__XXX
 SG_ PDM_Output_1_Current m0 : 8|8@1+ (0.5,0) [0|127.5] "A" Vector__XXX
 SG_ PDM_Out_Current_Compound_ID M : 4|4@1- (1,0) [0|240] "A" Vector__XXX
 SG_ PDM_Output_9_Current m1 : 16|8@1+ (0.2,0) [0|51] "A" Vector__XXX
 SG_ PDM_Output_32_Current m4 : 32|8@1+ (0.2,0) [0|51] "A" Vector__XXX
 SG_ PDM_Output_31_Current m4 : 24|8@1+ (0.2,0) [0|51] "A" Vector__XXX
 SG_ PDM_Output_30_Current m4 : 16|8@1+ (0.2,0) [0|51] "A" Vector__XXX
 SG_ PDM_Output_29_Current m4 : 8|8@1+ (0.2,0) [0|51] "A" Vector__XXX
 SG_ PDM_Output_28_Current m3 : 56|8@1+ (0.2,0) [0|51] "A" Vector__XXX
 SG_ PDM_Output_27_Current m3 : 48|8@1+ (0.2,0) [0|51] "A" Vector__XXX
 SG_ PDM_Output_26_Current m3 : 40|8@1+ (0.2,0) [0|51] "A" Vector__XXX
 SG_ PDM_Output_25_Current m3 : 32|8@1+ (0.2,0) [0|51] "A" Vector__XXX
 SG_ PDM_Output_24_Current m3 : 24|8@1+ (0.2,0) [0|51] "A" Vector__XXX
 SG_ PDM_Output_23_Current m3 : 16|8@1+ (0.2,0) [0|51] "A" Vector__XXX
 SG_ PDM_Output_22_Current m3 : 8|8@1+ (0.2,0) [0|51] "A" Vector__XXX
 SG_ PDM_Output_21_Current m2 : 56|8@1+ (0.2,0) [0|51] "A" Vector__XXX
 SG_ PDM_Output_20_Current m2 : 48|8@1+ (0.2,0) [0|51] "A" Vector__XXX
 SG_ PDM_Output_19_Current m2 : 40|8@1+ (0.2,0) [0|51] "A" Vector__XXX
 SG_ PDM_Output_18_Current m2 : 32|8@1+ (0.2,0) [0|51] "A" Vector__XXX
 SG_ PDM_Output_17_Current m2 : 24|8@1+ (0.2,0) [0|51] "A" Vector__XXX
 SG_ PDM_Output_16_Current m2 : 16|8@1+ (0.2,0) [0|51] "A" Vector__XXX
 SG_ PDM_Output_15_Current m2 : 8|8@1+ (0.2,0) [0|51] "A" Vector__XXX
 SG_ PDM_Output_14_Current m1 : 56|8@1+ (0.2,0) [0|51] "A" Vector__XXX
 SG_ PDM_Output_13_Current m1 : 48|8@1+ (0.2,0) [0|51] "A" Vector__XXX
 SG_ PDM_Output_12_Current m1 : 40|8@1+ (0.2,0) [0|51] "A" Vector__XXX
 SG_ PDM_Output_11_Current m1 : 32|8@1+ (0.2,0) [0|51] "A" Vector__XXX
 SG_ PDM_Output_10_Current m1 : 24|8@1+ (0.2,0) [0|51] "A" Vector__XXX

BO_ 1280 PDM_State: 8 Vector__XXX
 SG_ PDM_Output_Fault_9_16 m4 : 48|8@1- (1,0) [0|0] "Off/On" Vector__XXX
 SG_ PDM_Output_Fault_25_32 m4 : 32|8@1- (1,0) [0|0] "Off/On" Vector__XXX
 SG_ PDM_Output_Fault_1_8 m4 : 56|8@1- (1,0) [0|0] "Off/On" Vector__XXX
 SG_ PDM_Output_Fault_17_24 m4 : 40|8@1- (1,0) [0|0] "Off/On" Vector__XXX
 SG_ PDM_Total_Current m3 : 32|8@1+ (1,0) [0|255] "A" Vector__XXX
 SG_ PDM_Reset_Source m3 : 48|8@1- (1,0) [0|0] "Off/On" Vector__XXX
 SG_ PDM_Global_Error_Flag m3 : 24|8@1- (1,0) [0|0] "Off/On" Vector__XXX
 SG_ PDM_9V5_Internal m3 : 40|8@1+ (0.0615,0) [0|15.6825] "V" Vector__XXX
 SG_ PDM_Battery_Voltage m3 : 16|8@1+ (0.1216,0) [0|31.008] "V" Vector__XXX
 SG_ PDM_Internal_Temp m3 : 8|8@1+ (2,0) [0|125] "C" Vector__XXX
 SG_ PDM_State_Compound_ID M : 4|4@1- (1,0) [0|240] "Off/On" Vector__XXX
 SG_ PDM_Input_23_State m2 : 48|1@1- (1,0) [0|0] "Off/On" Vector__XXX
 SG_ PDM_Input_22_State m2 : 40|1@1- (1,0) [0|0] "Off/On" Vector__XXX
 SG_ PDM_Input_21_State m2 : 32|1@1- (1,0) [0|0] "Off/On" Vector__XXX
 SG_ PDM_Input_20_State m2 : 24|1@1- (1,0) [0|0] "Off/On" Vector__XXX
 SG_ PDM_Input_19_State m2 : 16|1@1- (1,0) [0|0] "Off/On" Vector__XXX
 SG_ PDM_Input_18_State m2 : 8|1@1- (1,0) [0|0] "Off/On" Vector__XXX
 SG_ PDM_Input_17_State m2 : 0|1@1- (1,0) [0|0] "Off/On" Vector__XXX
 SG_ PDM_Input_16_State m1 : 56|1@1- (1,0) [0|0] "Off/On" Vector__XXX
 SG_ PDM_Input_15_State m1 : 48|1@1- (1,0) [0|0] "Off/On" Vector__XXX
 SG_ PDM_Input_14_State m1 : 40|1@1- (1,0) [0|0] "Off/On" Vector__XXX
 SG_ PDM_Input_13_State m1 : 32|1@1- (1,0) [0|0] "Off/On" Vector__XXX
 SG_ PDM_Input_12_State m1 : 24|1@1- (1,0) [0|0] "Off/On" Vector__XXX
 SG_ PDM_Input_11_State m1 : 16|1@1- (1,0) [0|0] "Off/On" Vector__XXX
 SG_ PDM_Input_10_State m1 : 8|1@1- (1,0) [0|0] "Off/On" Vector__XXX
 SG_ PDM_Input_9_State m1 : 0|1@1- (1,0) [0|0] "Off/On" Vector__XXX
 SG_ PDM_Input_8_State m0 : 56|1@1- (1,7) [0|1] "Off/On" Vector__XXX
 SG_ PDM_Input_7_State m0 : 48|1@1- (1,6) [0|1] "Off/On" Vector__XXX
 SG_ PDM_Input_6_State m0 : 40|1@1- (1,5) [0|1] "Off/On" Vector__XXX
 SG_ PDM_Input_5_State m0 : 32|1@1- (1,4) [0|1] "Off/On" Vector__XXX
 SG_ PDM_Input_4_State m0 : 24|1@1- (1,3) [0|1] "Off/On" Vector__XXX
 SG_ PDM_Input_3_State m0 : 16|1@1- (1,12) [0|1] "Off/On" Vector__XXX
 SG_ PDM_Input_2_State m0 : 8|1@1- (1,9) [0|1] "Off/On" Vector__XXX
 SG_ PDM_Input_1_State m0 : 0|1@1- (1,0) [0|1] "Off/On" Vector__XXX

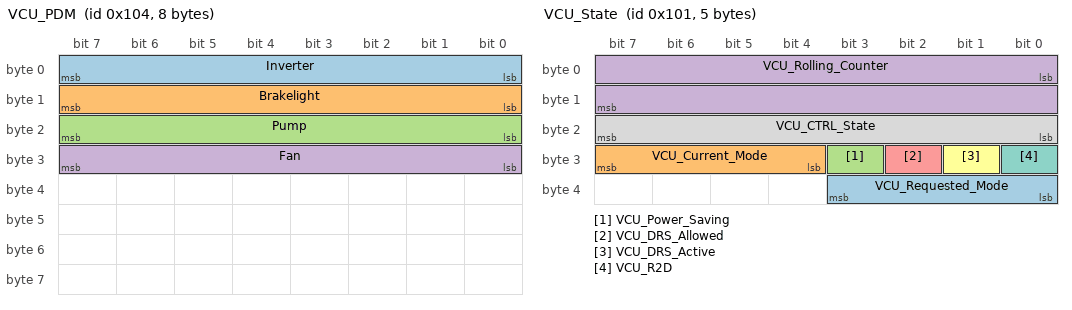
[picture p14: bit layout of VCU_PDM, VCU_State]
BO_ 260 VCU_PDM: 8 VCU
 SG_ Inverter : 0|8@1+ (1,0) [0|1] "Off/On" Vector__XXX
 SG_ Brakelight : 8|8@1+ (1,0) [0|1] "Off/On" Vector__XXX
 SG_ Pump : 16|8@1+ (1,0) [0|1] "Off/On" Vector__XXX
 SG_ Fan : 24|8@1+ (1,0) [0|1] "Off/On" Vector__XXX

BO_ 257 VCU_State: 5 VCU
 SG_ VCU_Requested_Mode : 32|4@1+ (1,0) [1|12] "" Vector__XXX
 SG_ VCU_Current_Mode : 28|4@1+ (1,0) [1|12] "" Vector__XXX
 SG_ VCU_Power_Saving : 27|1@1+ (1,0) [0|1] "" Vector__XXX
 SG_ VCU_Rolling_Counter : 0|16@1+ (1,0) [0|65535] "" Vector__XXX
 SG_ VCU_DRS_Allowed : 26|1@1+ (1,0) [0|1] "" Vector__XXX
 SG_ VCU_DRS_Active : 25|1@1+ (1,0) [0|1] "" Vector__XXX
 SG_ VCU_R2D : 24|1@1+ (1,0) [0|1] "" Vector__XXX
 SG_ VCU_CTRL_State : 16|8@1+ (1,0) [0|255] "" Vector__XXX

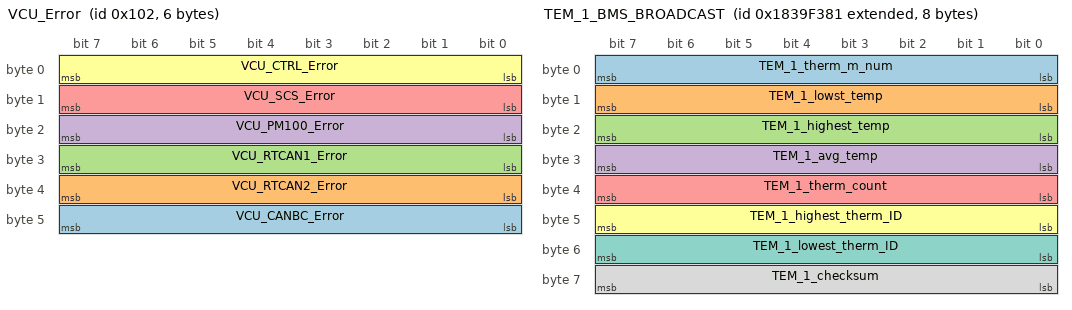
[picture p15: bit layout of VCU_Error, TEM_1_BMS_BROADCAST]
BO_ 258 VCU_Error: 6 VCU
 SG_ VCU_CANBC_Error : 40|8@1+ (1,0) [0|255] "" Vector__XXX
 SG_ VCU_RTCAN2_Error : 32|8@1+ (1,0) [0|255] "" Vector__XXX
 SG_ VCU_RTCAN1_Error : 24|8@1+ (1,0) [0|255] "" Vector__XXX
 SG_ VCU_PM100_Error : 16|8@1+ (1,0) [0|255] "" Vector__XXX
 SG_ VCU_SCS_Error : 8|8@1+ (1,0) [0|255] "" Vector__XXX
 SG_ VCU_CTRL_Error : 0|8@1+ (1,0) [0|255] "" Vector__XXX

BO_ 2553934721 TEM_1_BMS_BROADCAST: 8 Vector__XXX
 SG_ TEM_1_therm_m_num : 0|8@1+ (1,0) [0|255] "" Vector__XXX
 SG_ TEM_1_lowst_temp : 8|8@1- (1,0) [-128|127] "'C" Vector__XXX
 SG_ TEM_1_highest_temp : 16|8@1- (1,0) [-128|127] "'C" Vector__XXX
 SG_ TEM_1_avg_temp : 24|8@1- (1,0) [-128|127] "'C" Vector__XXX
 SG_ TEM_1_therm_count : 32|8@1+ (1,0) [0|255] "" Vector__XXX
 SG_ TEM_1_highest_therm_ID : 40|8@1+ (1,0) [0|255] "" Vector__XXX
 SG_ TEM_1_lowest_therm_ID : 48|8@1+ (1,0) [0|255] "" Vector__XXX
 SG_ TEM_1_checksum : 56|8@1+ (1,0) [0|255] "" Vector__XXX

BO_ 2553869185 TEM_1_GENERAL_BROADCAST: 8 Vector__XXX
 SG_ TEM_1_relative_therm_ID M : 15|8@0+ (1,0) [0|255] "" Vector__XXX
 SG_ TEM_1_therm_080_value m80 : 16|8@1- (1,0) [-128|127] "'C" Vector__XXX
 SG_ TEM_1_therm_081_value m81 : 16|8@1- (1,0) [-128|127] "'C" Vector__XXX
 SG_ TEM_1_therm_082_value m82 : 16|8@1- (1,0) [-128|127] "'C" Vector__XXX
 SG_ TEM_1_therm_083_value m83 : 16|8@1- (1,0) [-128|127] "'C" Vector__XXX
 SG_ TEM_1_therm_084_value m84 : 16|8@1- (1,0) [-128|127] "'C" Vector__XXX
 SG_ TEM_1_therm_085_value m85 : 16|8@1- (1,0) [-128|127] "'C" Vector__XXX
 SG_ TEM_1_therm_086_value m86 : 16|8@1- (1,0) [-128|127] "'C" Vector__XXX
 SG_ TEM_1_therm_087_value m87 : 16|8@1- (1,0) [-128|127] "'C" Vector__XXX
 SG_ TEM_1_therm_088_value m88 : 16|8@1- (1,0) [-128|127] "'C" Vector__XXX
 SG_ TEM_1_therm_089_value m89 : 16|8@1- (1,0) [-128|127] "'C" Vector__XXX
 SG_ TEM_1_therm_090_value m90 : 16|8@1- (1,0) [-128|127] "'C" Vector__XXX
 SG_ TEM_1_therm_091_value m91 : 16|8@1- (1,0) [-128|127] "'C" Vector__XXX
 SG_ TEM_1_therm_092_value m92 : 16|8@1- (1,0) [-128|127] "'C" Vector__XXX
 SG_ TEM_1_therm_093_value m93 : 16|8@1- (1,0) [-128|127] "'C" Vector__XXX
 SG_ TEM_1_therm_094_value m94 : 16|8@1- (1,0) [-128|127] "'C" Vector__XXX
 SG_ TEM_1_therm_095_value m95 : 16|8@1- (1,0) [-128|127] "'C" Vector__XXX
 SG_ TEM_1_therm_096_value m96 : 16|8@1- (1,0) [-128|127] "'C" Vector__XXX
 SG_ TEM_1_therm_097_value m97 : 16|8@1- (1,0) [-128|127] "'C" Vector__XXX
 SG_ TEM_1_therm_098_value m98 : 16|8@1- (1,0) [-128|127] "'C" Vector__XXX
 SG_ TEM_1_therm_099_value m99 : 16|8@1- (1,0) [-128|127] "'C" Vector__XXX
 SG_ TEM_1_therm_100_value m100 : 16|8@1- (1,0) [-128|127] "'C" Vector__XXX
 SG_ TEM_1_therm_101_value m101 : 16|8@1- (1,0) [-128|127] "'C" Vector__XXX
 SG_ TEM_1_therm_102_value m102 : 16|8@1- (1,0) [-128|127] "'C" Vector__XXX
 SG_ TEM_1_therm_103_value m103 : 16|8@1- (1,0) [-128|127] "'C" Vector__XXX
 SG_ TEM_1_therm_count : 24|8@1+ (1,0) [0|255] "" Vector__XXX
 SG_ TEM_1_lowest_temp : 32|8@1- (1,0) [-128|127] "'C" Vector__XXX
 SG_ TEM_1_Highest_temp : 40|8@1- (1,0) [-128|127] "'C" Vector__XXX
 SG_ TEM_1_highest_therm_ID : 48|8@1+ (1,0) [0|255] "" Vector__XXX
 SG_ TEM_1_Lowest_therm_ID : 56|8@1+ (1,0) [0|255] "" Vector__XXX

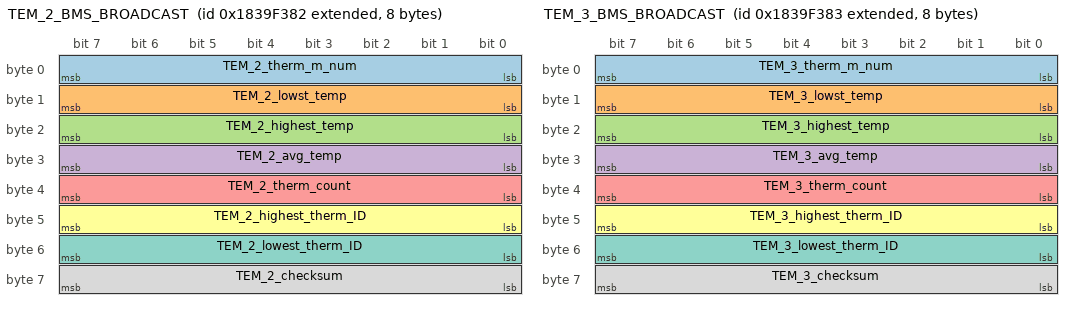
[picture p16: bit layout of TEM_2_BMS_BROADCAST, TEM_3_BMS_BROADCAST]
BO_ 2553934722 TEM_2_BMS_BROADCAST: 8 Vector__XXX
 SG_ TEM_2_therm_m_num : 0|8@1+ (1,0) [0|255] "" Vector__XXX
 SG_ TEM_2_lowst_temp : 8|8@1- (1,0) [-128|127] "'C" Vector__XXX
 SG_ TEM_2_highest_temp : 16|8@1- (1,0) [-128|127] "'C" Vector__XXX
 SG_ TEM_2_avg_temp : 24|8@1- (1,0) [-128|127] "'C" Vector__XXX
 SG_ TEM_2_therm_count : 32|8@1+ (1,0) [0|255] "" Vector__XXX
 SG_ TEM_2_highest_therm_ID : 40|8@1+ (1,0) [0|255] "" Vector__XXX
 SG_ TEM_2_lowest_therm_ID : 48|8@1+ (1,0) [0|255] "" Vector__XXX
 SG_ TEM_2_checksum : 56|8@1+ (1,0) [0|255] "" Vector__XXX

BO_ 2553869186 TEM_2_GENERAL_BROADCAST: 8 Vector__XXX
 SG_ TEM_2_relative_therm_ID M : 15|8@0+ (1,0) [0|255] "" Vector__XXX
 SG_ TEM_2_therm_160_value m160 : 16|8@1- (1,0) [-128|127] "'C" Vector__XXX
 SG_ TEM_2_therm_161_value m161 : 16|8@1- (1,0) [-128|127] "'C" Vector__XXX
 SG_ TEM_2_therm_162_value m162 : 16|8@1- (1,0) [-128|127] "'C" Vector__XXX
 SG_ TEM_2_therm_163_value m163 : 16|8@1- (1,0) [-128|127] "'C" Vector__XXX
 SG_ TEM_2_therm_164_value m164 : 16|8@1- (1,0) [-128|127] "'C" Vector__XXX
 SG_ TEM_2_therm_165_value m165 : 16|8@1- (1,0) [-128|127] "'C" Vector__XXX
 SG_ TEM_2_therm_166_value m166 : 16|8@1- (1,0) [-128|127] "'C" Vector__XXX
 SG_ TEM_2_therm_167_value m167 : 16|8@1- (1,0) [-128|127] "'C" Vector__XXX
 SG_ TEM_2_therm_168_value m168 : 16|8@1- (1,0) [-128|127] "'C" Vector__XXX
 SG_ TEM_2_therm_169_value m169 : 16|8@1- (1,0) [-128|127] "'C" Vector__XXX
 SG_ TEM_2_therm_170_value m170 : 16|8@1- (1,0) [-128|127] "'C" Vector__XXX
 SG_ TEM_2_therm_171_value m171 : 16|8@1- (1,0) [-128|127] "'C" Vector__XXX
 SG_ TEM_2_therm_172_value m172 : 16|8@1- (1,0) [-128|127] "'C" Vector__XXX
 SG_ TEM_2_therm_173_value m173 : 16|8@1- (1,0) [-128|127] "'C" Vector__XXX
 SG_ TEM_2_therm_174_value m174 : 16|8@1- (1,0) [-128|127] "'C" Vector__XXX
 SG_ TEM_2_therm_175_value m175 : 16|8@1- (1,0) [-128|127] "'C" Vector__XXX
 SG_ TEM_2_therm_176_value m176 : 16|8@1- (1,0) [-128|127] "'C" Vector__XXX
 SG_ TEM_2_therm_177_value m177 : 16|8@1- (1,0) [-128|127] "'C" Vector__XXX
 SG_ TEM_2_therm_178_value m178 : 16|8@1- (1,0) [-128|127] "'C" Vector__XXX
 SG_ TEM_2_therm_179_value m179 : 16|8@1- (1,0) [-128|127] "'C" Vector__XXX
 SG_ TEM_2_therm_180_value m180 : 16|8@1- (1,0) [-128|127] "'C" Vector__XXX
 SG_ TEM_2_therm_181_value m181 : 16|8@1- (1,0) [-128|127] "'C" Vector__XXX
 SG_ TEM_2_therm_182_value m182 : 16|8@1- (1,0) [-128|127] "'C" Vector__XXX
 SG_ TEM_2_therm_183_value m183 : 16|8@1- (1,0) [-128|127] "'C" Vector__XXX
 SG_ TEM_2_therm_count : 24|8@1+ (1,0) [0|255] "" Vector__XXX
 SG_ TEM_2_lowest_temp : 32|8@1- (1,0) [-128|127] "'C" Vector__XXX
 SG_ TEM_2_Highest_temp : 40|8@1- (1,0) [-128|127] "'C" Vector__XXX
 SG_ TEM_2_highest_therm_ID : 48|8@1+ (1,0) [0|255] "" Vector__XXX
 SG_ TEM_2_Lowest_therm_ID : 56|8@1+ (1,0) [0|255] "" Vector__XXX

BO_ 2553934723 TEM_3_BMS_BROADCAST: 8 Vector__XXX
 SG_ TEM_3_therm_m_num : 0|8@1+ (1,0) [0|255] "" Vector__XXX
 SG_ TEM_3_lowst_temp : 8|8@1- (1,0) [-128|127] "'C" Vector__XXX
 SG_ TEM_3_highest_temp : 16|8@1- (1,0) [-128|127] "'C" Vector__XXX
 SG_ TEM_3_avg_temp : 24|8@1- (1,0) [-128|127] "'C" Vector__XXX
 SG_ TEM_3_therm_count : 32|8@1+ (1,0) [0|255] "" Vector__XXX
 SG_ TEM_3_highest_therm_ID : 40|8@1+ (1,0) [0|255] "" Vector__XXX
 SG_ TEM_3_lowest_therm_ID : 48|8@1+ (1,0) [0|255] "" Vector__XXX
 SG_ TEM_3_checksum : 56|8@1+ (1,0) [0|255] "" Vector__XXX

BO_ 2553869187 TEM_3_GENERAL_BROADCAST: 8 Vector__XXX
 SG_ TEM_3_relative_therm_ID M : 15|8@0+ (1,0) [0|255] "" Vector__XXX
 SG_ TEM_3_therm_000_value m0 : 16|8@1- (1,0) [-128|127] "'C" Vector__XXX
 SG_ TEM_3_therm_001_value m1 : 16|8@1- (1,0) [-128|127] "'C" Vector__XXX
 SG_ TEM_3_therm_002_value m2 : 16|8@1- (1,0) [-128|127] "'C" Vector__XXX
 SG_ TEM_3_therm_003_value m3 : 16|8@1- (1,0) [-128|127] "'C" Vector__XXX
 SG_ TEM_3_therm_004_value m4 : 16|8@1- (1,0) [-128|127] "'C" Vector__XXX
 SG_ TEM_3_therm_005_value m5 : 16|8@1- (1,0) [-128|127] "'C" Vector__XXX
 SG_ TEM_3_therm_006_value m6 : 16|8@1- (1,0) [-128|127] "'C" Vector__XXX
 SG_ TEM_3_therm_007_value m7 : 16|8@1- (1,0) [-128|127] "'C" Vector__XXX
 SG_ TEM_3_therm_240_value m240 : 16|8@1- (1,0) [-128|127] "'C" Vector__XXX
 SG_ TEM_3_therm_241_value m241 : 16|8@1- (1,0) [-128|127] "'C" Vector__XXX
 SG_ TEM_3_therm_242_value m242 : 16|8@1- (1,0) [-128|127] "'C" Vector__XXX
 SG_ TEM_3_therm_243_value m243 : 16|8@1- (1,0) [-128|127] "'C" Vector__XXX
 SG_ TEM_3_therm_244_value m244 : 16|8@1- (1,0) [-128|127] "'C" Vector__XXX
 SG_ TEM_3_therm_245_value m245 : 16|8@1- (1,0) [-128|127] "'C" Vector__XXX
 SG_ TEM_3_therm_246_value m246 : 16|8@1- (1,0) [-128|127] "'C" Vector__XXX
 SG_ TEM_3_therm_247_value m247 : 16|8@1- (1,0) [-128|127] "'C" Vector__XXX
 SG_ TEM_3_therm_248_value m248 : 16|8@1- (1,0) [-128|127] "'C" Vector__XXX
 SG_ TEM_3_therm_249_value m249 : 16|8@1- (1,0) [-128|127] "'C" Vector__XXX
 SG_ TEM_3_therm_250_value m250 : 16|8@1- (1,0) [-128|127] "'C" Vector__XXX
 SG_ TEM_3_therm_251_value m251 : 16|8@1- (1,0) [-128|127] "'C" Vector__XXX
 SG_ TEM_3_therm_252_value m252 : 16|8@1- (1,0) [-128|127] "'C" Vector__XXX
 SG_ TEM_3_therm_253_value m253 : 16|8@1- (1,0) [-128|127] "'C" Vector__XXX
 SG_ TEM_3_therm_254_value m254 : 16|8@1- (1,0) [-128|127] "'C" Vector__XXX
 SG_ TEM_3_therm_255_value m255 : 16|8@1- (1,0) [-128|127] "'C" Vector__XXX
 SG_ TEM_3_therm_count : 24|8@1+ (1,0) [0|255] "" Vector__XXX
 SG_ TEM_3_lowest_temp : 32|8@1- (1,0) [-128|127] "'C" Vector__XXX
 SG_ TEM_3_Highest_temp : 40|8@1- (1,0) [-128|127] "'C" Vector__XXX
 SG_ TEM_3_highest_therm_ID : 48|8@1+ (1,0) [0|255] "" Vector__XXX
 SG_ TEM_3_Lowest_therm_ID : 56|8@1+ (1,0) [0|255] "" Vector__XXX

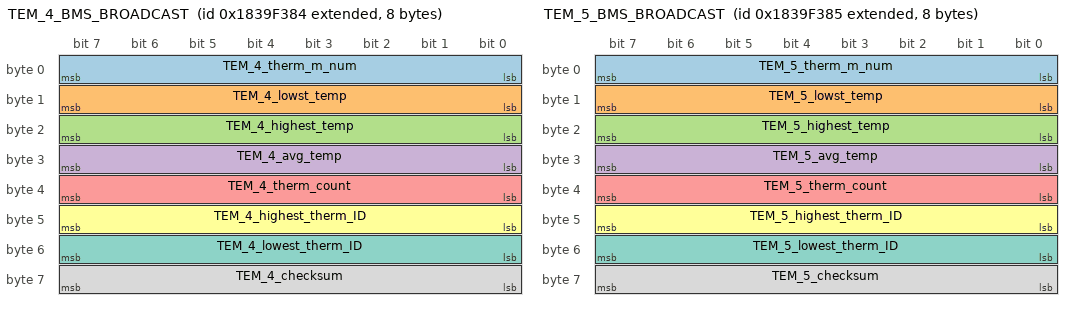
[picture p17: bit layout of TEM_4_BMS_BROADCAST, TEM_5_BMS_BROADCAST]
BO_ 2553934724 TEM_4_BMS_BROADCAST: 8 Vector__XXX
 SG_ TEM_4_therm_m_num : 0|8@1+ (1,0) [0|255] "" Vector__XXX
 SG_ TEM_4_lowst_temp : 8|8@1- (1,0) [-128|127] "'C" Vector__XXX
 SG_ TEM_4_highest_temp : 16|8@1- (1,0) [-128|127] "'C" Vector__XXX
 SG_ TEM_4_avg_temp : 24|8@1- (1,0) [-128|127] "'C" Vector__XXX
 SG_ TEM_4_therm_count : 32|8@1+ (1,0) [0|255] "" Vector__XXX
 SG_ TEM_4_highest_therm_ID : 40|8@1+ (1,0) [0|255] "" Vector__XXX
 SG_ TEM_4_lowest_therm_ID : 48|8@1+ (1,0) [0|255] "" Vector__XXX
 SG_ TEM_4_checksum : 56|8@1+ (1,0) [0|255] "" Vector__XXX

BO_ 2553869188 TEM_4_GENERAL_BROADCAST: 8 Vector__XXX
 SG_ TEM_4_relative_therm_ID M : 15|8@0+ (1,0) [0|255] "" Vector__XXX
 SG_ TEM_4_therm_064_value m64 : 16|8@1- (1,0) [-128|127] "'C" Vector__XXX
 SG_ TEM_4_therm_065_value m65 : 16|8@1- (1,0) [-128|127] "'C" Vector__XXX
 SG_ TEM_4_therm_066_value m66 : 16|8@1- (1,0) [-128|127] "'C" Vector__XXX
 SG_ TEM_4_therm_067_value m67 : 16|8@1- (1,0) [-128|127] "'C" Vector__XXX
 SG_ TEM_4_therm_068_value m68 : 16|8@1- (1,0) [-128|127] "'C" Vector__XXX
 SG_ TEM_4_therm_069_value m69 : 16|8@1- (1,0) [-128|127] "'C" Vector__XXX
 SG_ TEM_4_therm_070_value m70 : 16|8@1- (1,0) [-128|127] "'C" Vector__XXX
 SG_ TEM_4_therm_071_value m71 : 16|8@1- (1,0) [-128|127] "'C" Vector__XXX
 SG_ TEM_4_therm_072_value m72 : 16|8@1- (1,0) [-128|127] "'C" Vector__XXX
 SG_ TEM_4_therm_073_value m73 : 16|8@1- (1,0) [-128|127] "'C" Vector__XXX
 SG_ TEM_4_therm_074_value m74 : 16|8@1- (1,0) [-128|127] "'C" Vector__XXX
 SG_ TEM_4_therm_075_value m75 : 16|8@1- (1,0) [-128|127] "'C" Vector__XXX
 SG_ TEM_4_therm_076_value m76 : 16|8@1- (1,0) [-128|127] "'C" Vector__XXX
 SG_ TEM_4_therm_077_value m77 : 16|8@1- (1,0) [-128|127] "'C" Vector__XXX
 SG_ TEM_4_therm_078_value m78 : 16|8@1- (1,0) [-128|127] "'C" Vector__XXX
 SG_ TEM_4_therm_079_value m79 : 16|8@1- (1,0) [-128|127] "'C" Vector__XXX
 SG_ TEM_4_therm_080_value m80 : 16|8@1- (1,0) [-128|127] "'C" Vector__XXX
 SG_ TEM_4_therm_081_value m81 : 16|8@1- (1,0) [-128|127] "'C" Vector__XXX
 SG_ TEM_4_therm_082_value m82 : 16|8@1- (1,0) [-128|127] "'C" Vector__XXX
 SG_ TEM_4_therm_083_value m83 : 16|8@1- (1,0) [-128|127] "'C" Vector__XXX
 SG_ TEM_4_therm_084_value m84 : 16|8@1- (1,0) [-128|127] "'C" Vector__XXX
 SG_ TEM_4_therm_085_value m85 : 16|8@1- (1,0) [-128|127] "'C" Vector__XXX
 SG_ TEM_4_therm_086_value m86 : 16|8@1- (1,0) [-128|127] "'C" Vector__XXX
 SG_ TEM_4_therm_087_value m87 : 16|8@1- (1,0) [-128|127] "'C" Vector__XXX
 SG_ TEM_4_therm_count : 24|8@1+ (1,0) [0|255] "" Vector__XXX
 SG_ TEM_4_lowest_temp : 32|8@1- (1,0) [-128|127] "'C" Vector__XXX
 SG_ TEM_4_Highest_temp : 40|8@1- (1,0) [-128|127] "'C" Vector__XXX
 SG_ TEM_4_highest_therm_ID : 48|8@1+ (1,0) [0|255] "" Vector__XXX
 SG_ TEM_4_Lowest_therm_ID : 56|8@1+ (1,0) [0|255] "" Vector__XXX

BO_ 2553934725 TEM_5_BMS_BROADCAST: 8 Vector__XXX
 SG_ TEM_5_therm_m_num : 0|8@1+ (1,0) [0|255] "" Vector__XXX
 SG_ TEM_5_lowst_temp : 8|8@1- (1,0) [-128|127] "'C" Vector__XXX
 SG_ TEM_5_highest_temp : 16|8@1- (1,0) [-128|127] "'C" Vector__XXX
 SG_ TEM_5_avg_temp : 24|8@1- (1,0) [-128|127] "'C" Vector__XXX
 SG_ TEM_5_therm_count : 32|8@1+ (1,0) [0|255] "" Vector__XXX
 SG_ TEM_5_highest_therm_ID : 40|8@1+ (1,0) [0|255] "" Vector__XXX
 SG_ TEM_5_lowest_therm_ID : 48|8@1+ (1,0) [0|255] "" Vector__XXX
 SG_ TEM_5_checksum : 56|8@1+ (1,0) [0|255] "" Vector__XXX

BO_ 2553869189 TEM_5_GENERAL_BROADCAST: 8 Vector__XXX
 SG_ TEM_5_relative_therm_ID M : 15|8@0+ (1,0) [0|255] "" Vector__XXX
 SG_ TEM_5_therm_144_value m144 : 16|8@1- (1,0) [-128|127] "'C" Vector__XXX
 SG_ TEM_5_therm_145_value m145 : 16|8@1- (1,0) [-128|127] "'C" Vector__XXX
 SG_ TEM_5_therm_146_value m146 : 16|8@1- (1,0) [-128|127] "'C" Vector__XXX
 SG_ TEM_5_therm_147_value m147 : 16|8@1- (1,0) [-128|127] "'C" Vector__XXX
 SG_ TEM_5_therm_148_value m148 : 16|8@1- (1,0) [-128|127] "'C" Vector__XXX
 SG_ TEM_5_therm_149_value m149 : 16|8@1- (1,0) [-128|127] "'C" Vector__XXX
 SG_ TEM_5_therm_150_value m150 : 16|8@1- (1,0) [-128|127] "'C" Vector__XXX
 SG_ TEM_5_therm_151_value m151 : 16|8@1- (1,0) [-128|127] "'C" Vector__XXX
 SG_ TEM_5_therm_152_value m152 : 16|8@1- (1,0) [-128|127] "'C" Vector__XXX
 SG_ TEM_5_therm_153_value m153 : 16|8@1- (1,0) [-128|127] "'C" Vector__XXX
 SG_ TEM_5_therm_154_value m154 : 16|8@1- (1,0) [-128|127] "'C" Vector__XXX
 SG_ TEM_5_therm_155_value m155 : 16|8@1- (1,0) [-128|127] "'C" Vector__XXX
 SG_ TEM_5_therm_156_value m156 : 16|8@1- (1,0) [-128|127] "'C" Vector__XXX
 SG_ TEM_5_therm_157_value m157 : 16|8@1- (1,0) [-128|127] "'C" Vector__XXX
 SG_ TEM_5_therm_158_value m158 : 16|8@1- (1,0) [-128|127] "'C" Vector__XXX
 SG_ TEM_5_therm_159_value m159 : 16|8@1- (1,0) [-128|127] "'C" Vector__XXX
 SG_ TEM_5_therm_160_value m160 : 16|8@1- (1,0) [-128|127] "'C" Vector__XXX
 SG_ TEM_5_therm_161_value m161 : 16|8@1- (1,0) [-128|127] "'C" Vector__XXX
 SG_ TEM_5_therm_162_value m162 : 16|8@1- (1,0) [-128|127] "'C" Vector__XXX
 SG_ TEM_5_therm_163_value m163 : 16|8@1- (1,0) [-128|127] "'C" Vector__XXX
 SG_ TEM_5_therm_164_value m164 : 16|8@1- (1,0) [-128|127] "'C" Vector__XXX
 SG_ TEM_5_therm_165_value m165 : 16|8@1- (1,0) [-128|127] "'C" Vector__XXX
 SG_ TEM_5_therm_166_value m166 : 16|8@1- (1,0) [-128|127] "'C" Vector__XXX
 SG_ TEM_5_therm_167_value m167 : 16|8@1- (1,0) [-128|127] "'C" Vector__XXX
 SG_ TEM_5_therm_count : 24|8@1+ (1,0) [0|255] "" Vector__XXX
 SG_ TEM_5_lowest_temp : 32|8@1- (1,0) [-128|127] "'C" Vector__XXX
 SG_ TEM_5_Highest_temp : 40|8@1- (1,0) [-128|127] "'C" Vector__XXX
 SG_ TEM_5_highest_therm_ID : 48|8@1+ (1,0) [0|255] "" Vector__XXX
 SG_ TEM_5_Lowest_therm_ID : 56|8@1+ (1,0) [0|255] "" Vector__XXX

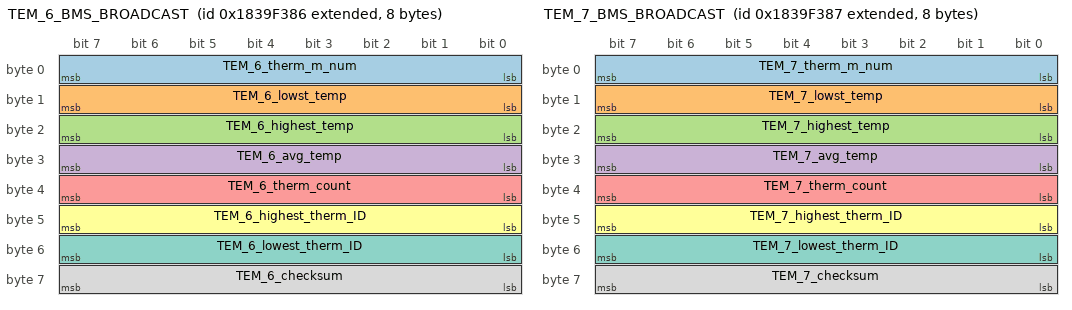
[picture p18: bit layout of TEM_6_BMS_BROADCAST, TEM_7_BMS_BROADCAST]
BO_ 2553934726 TEM_6_BMS_BROADCAST: 8 Vector__XXX
 SG_ TEM_6_therm_m_num : 0|8@1+ (1,0) [0|255] "" Vector__XXX
 SG_ TEM_6_lowst_temp : 8|8@1- (1,0) [-128|127] "'C" Vector__XXX
 SG_ TEM_6_highest_temp : 16|8@1- (1,0) [-128|127] "'C" Vector__XXX
 SG_ TEM_6_avg_temp : 24|8@1- (1,0) [-128|127] "'C" Vector__XXX
 SG_ TEM_6_therm_count : 32|8@1+ (1,0) [0|255] "" Vector__XXX
 SG_ TEM_6_highest_therm_ID : 40|8@1+ (1,0) [0|255] "" Vector__XXX
 SG_ TEM_6_lowest_therm_ID : 48|8@1+ (1,0) [0|255] "" Vector__XXX
 SG_ TEM_6_checksum : 56|8@1+ (1,0) [0|255] "" Vector__XXX

BO_ 2553869190 TEM_6_GENERAL_BROADCAST: 8 Vector__XXX
 SG_ TEM_6_relative_therm_ID M : 15|8@0+ (1,0) [0|255] "" Vector__XXX
 SG_ TEM_6_therm_224_value m224 : 16|8@1- (1,0) [-128|127] "'C" Vector__XXX
 SG_ TEM_6_therm_225_value m225 : 16|8@1- (1,0) [-128|127] "'C" Vector__XXX
 SG_ TEM_6_therm_226_value m226 : 16|8@1- (1,0) [-128|127] "'C" Vector__XXX
 SG_ TEM_6_therm_227_value m227 : 16|8@1- (1,0) [-128|127] "'C" Vector__XXX
 SG_ TEM_6_therm_228_value m228 : 16|8@1- (1,0) [-128|127] "'C" Vector__XXX
 SG_ TEM_6_therm_229_value m229 : 16|8@1- (1,0) [-128|127] "'C" Vector__XXX
 SG_ TEM_6_therm_230_value m230 : 16|8@1- (1,0) [-128|127] "'C" Vector__XXX
 SG_ TEM_6_therm_231_value m231 : 16|8@1- (1,0) [-128|127] "'C" Vector__XXX
 SG_ TEM_6_therm_232_value m232 : 16|8@1- (1,0) [-128|127] "'C" Vector__XXX
 SG_ TEM_6_therm_233_value m233 : 16|8@1- (1,0) [-128|127] "'C" Vector__XXX
 SG_ TEM_6_therm_234_value m234 : 16|8@1- (1,0) [-128|127] "'C" Vector__XXX
 SG_ TEM_6_therm_235_value m235 : 16|8@1- (1,0) [-128|127] "'C" Vector__XXX
 SG_ TEM_6_therm_236_value m236 : 16|8@1- (1,0) [-128|127] "'C" Vector__XXX
 SG_ TEM_6_therm_237_value m237 : 16|8@1- (1,0) [-128|127] "'C" Vector__XXX
 SG_ TEM_6_therm_238_value m238 : 16|8@1- (1,0) [-128|127] "'C" Vector__XXX
 SG_ TEM_6_therm_239_value m239 : 16|8@1- (1,0) [-128|127] "'C" Vector__XXX
 SG_ TEM_6_therm_240_value m240 : 16|8@1- (1,0) [-128|127] "'C" Vector__XXX
 SG_ TEM_6_therm_241_value m241 : 16|8@1- (1,0) [-128|127] "'C" Vector__XXX
 SG_ TEM_6_therm_242_value m242 : 16|8@1- (1,0) [-128|127] "'C" Vector__XXX
 SG_ TEM_6_therm_243_value m243 : 16|8@1- (1,0) [-128|127] "'C" Vector__XXX
 SG_ TEM_6_therm_244_value m244 : 16|8@1- (1,0) [-128|127] "'C" Vector__XXX
 SG_ TEM_6_therm_245_value m245 : 16|8@1- (1,0) [-128|127] "'C" Vector__XXX
 SG_ TEM_6_therm_246_value m246 : 16|8@1- (1,0) [-128|127] "'C" Vector__XXX
 SG_ TEM_6_therm_247_value m247 : 16|8@1- (1,0) [-128|127] "'C" Vector__XXX
 SG_ TEM_6_therm_count : 24|8@1+ (1,0) [0|255] "" Vector__XXX
 SG_ TEM_6_lowest_temp : 32|8@1- (1,0) [-128|127] "'C" Vector__XXX
 SG_ TEM_6_Highest_temp : 40|8@1- (1,0) [-128|127] "'C" Vector__XXX
 SG_ TEM_6_highest_therm_ID : 48|8@1+ (1,0) [0|255] "" Vector__XXX
 SG_ TEM_6_Lowest_therm_ID : 56|8@1+ (1,0) [0|255] "" Vector__XXX

BO_ 2553934727 TEM_7_BMS_BROADCAST: 8 Vector__XXX
 SG_ TEM_7_therm_m_num : 0|8@1+ (1,0) [0|255] "" Vector__XXX
 SG_ TEM_7_lowst_temp : 8|8@1- (1,0) [-128|127] "'C" Vector__XXX
 SG_ TEM_7_highest_temp : 16|8@1- (1,0) [-128|127] "'C" Vector__XXX
 SG_ TEM_7_avg_temp : 24|8@1- (1,0) [-128|127] "'C" Vector__XXX
 SG_ TEM_7_therm_count : 32|8@1+ (1,0) [0|255] "" Vector__XXX
 SG_ TEM_7_highest_therm_ID : 40|8@1+ (1,0) [0|255] "" Vector__XXX
 SG_ TEM_7_lowest_therm_ID : 48|8@1+ (1,0) [0|255] "" Vector__XXX
 SG_ TEM_7_checksum : 56|8@1+ (1,0) [0|255] "" Vector__XXX

BO_ 2553869191 TEM_7_GENERAL_BROADCAST: 8 Vector__XXX
 SG_ TEM_7_relative_therm_ID M : 15|8@0+ (1,0) [0|255] "" Vector__XXX
 SG_ TEM_7_therm_048_value m48 : 16|8@1- (1,0) [-128|127] "'C" Vector__XXX
 SG_ TEM_7_therm_049_value m49 : 16|8@1- (1,0) [-128|127] "'C" Vector__XXX
 SG_ TEM_7_therm_050_value m50 : 16|8@1- (1,0) [-128|127] "'C" Vector__XXX
 SG_ TEM_7_therm_051_value m51 : 16|8@1- (1,0) [-128|127] "'C" Vector__XXX
 SG_ TEM_7_therm_052_value m52 : 16|8@1- (1,0) [-128|127] "'C" Vector__XXX
 SG_ TEM_7_therm_053_value m53 : 16|8@1- (1,0) [-128|127] "'C" Vector__XXX
 SG_ TEM_7_therm_054_value m54 : 16|8@1- (1,0) [-128|127] "'C" Vector__XXX
 SG_ TEM_7_therm_055_value m55 : 16|8@1- (1,0) [-128|127] "'C" Vector__XXX
 SG_ TEM_7_therm_056_value m56 : 16|8@1- (1,0) [-128|127] "'C" Vector__XXX
 SG_ TEM_7_therm_057_value m57 : 16|8@1- (1,0) [-128|127] "'C" Vector__XXX
 SG_ TEM_7_therm_058_value m58 : 16|8@1- (1,0) [-128|127] "'C" Vector__XXX
 SG_ TEM_7_therm_059_value m59 : 16|8@1- (1,0) [-128|127] "'C" Vector__XXX
 SG_ TEM_7_therm_060_value m60 : 16|8@1- (1,0) [-128|127] "'C" Vector__XXX
 SG_ TEM_7_therm_061_value m61 : 16|8@1- (1,0) [-128|127] "'C" Vector__XXX
 SG_ TEM_7_therm_062_value m62 : 16|8@1- (1,0) [-128|127] "'C" Vector__XXX
 SG_ TEM_7_therm_063_value m63 : 16|8@1- (1,0) [-128|127] "'C" Vector__XXX
 SG_ TEM_7_therm_064_value m64 : 16|8@1- (1,0) [-128|127] "'C" Vector__XXX
 SG_ TEM_7_therm_065_value m65 : 16|8@1- (1,0) [-128|127] "'C" Vector__XXX
 SG_ TEM_7_therm_066_value m66 : 16|8@1- (1,0) [-128|127] "'C" Vector__XXX
 SG_ TEM_7_therm_067_value m67 : 16|8@1- (1,0) [-128|127] "'C" Vector__XXX
 SG_ TEM_7_therm_068_value m68 : 16|8@1- (1,0) [-128|127] "'C" Vector__XXX
 SG_ TEM_7_therm_069_value m69 : 16|8@1- (1,0) [-128|127] "'C" Vector__XXX
 SG_ TEM_7_therm_070_value m70 : 16|8@1- (1,0) [-128|127] "'C" Vector__XXX
 SG_ TEM_7_therm_071_value m71 : 16|8@1- (1,0) [-128|127] "'C" Vector__XXX
 SG_ TEM_7_therm_count : 24|8@1+ (1,0) [0|255] "" Vector__XXX
 SG_ TEM_7_lowest_temp : 32|8@1- (1,0) [-128|127] "'C" Vector__XXX
 SG_ TEM_7_Highest_temp : 40|8@1- (1,0) [-128|127] "'C" Vector__XXX
 SG_ TEM_7_highest_therm_ID : 48|8@1+ (1,0) [0|255] "" Vector__XXX
 SG_ TEM_7_Lowest_therm_ID : 56|8@1+ (1,0) [0|255] "" Vector__XXX

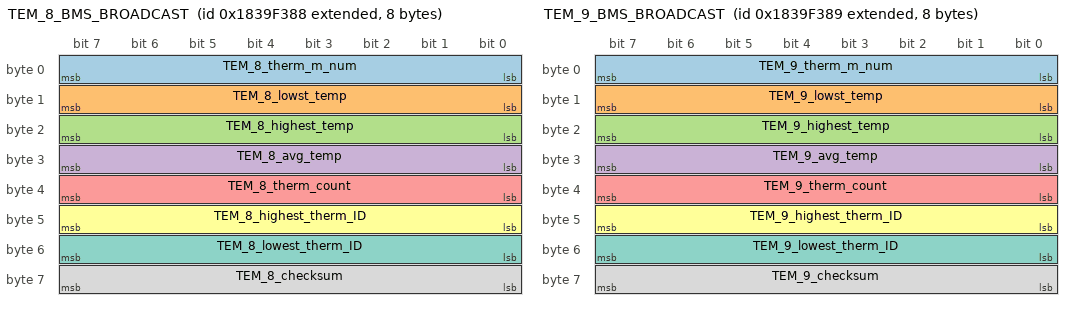
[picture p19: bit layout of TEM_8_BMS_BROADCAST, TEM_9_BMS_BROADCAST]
BO_ 2553934728 TEM_8_BMS_BROADCAST: 8 Vector__XXX
 SG_ TEM_8_therm_m_num : 0|8@1+ (1,0) [0|255] "" Vector__XXX
 SG_ TEM_8_lowst_temp : 8|8@1- (1,0) [-128|127] "'C" Vector__XXX
 SG_ TEM_8_highest_temp : 16|8@1- (1,0) [-128|127] "'C" Vector__XXX
 SG_ TEM_8_avg_temp : 24|8@1- (1,0) [-128|127] "'C" Vector__XXX
 SG_ TEM_8_therm_count : 32|8@1+ (1,0) [0|255] "" Vector__XXX
 SG_ TEM_8_highest_therm_ID : 40|8@1+ (1,0) [0|255] "" Vector__XXX
 SG_ TEM_8_lowest_therm_ID : 48|8@1+ (1,0) [0|255] "" Vector__XXX
 SG_ TEM_8_checksum : 56|8@1+ (1,0) [0|255] "" Vector__XXX

BO_ 2553869192 TEM_8_GENERAL_BROADCAST: 8 Vector__XXX
 SG_ TEM_8_relative_therm_ID M : 15|8@0+ (1,0) [0|255] "" Vector__XXX
 SG_ TEM_8_therm_128_value m128 : 16|8@1- (1,0) [-128|127] "'C" Vector__XXX
 SG_ TEM_8_therm_129_value m129 : 16|8@1- (1,0) [-128|127] "'C" Vector__XXX
 SG_ TEM_8_therm_130_value m130 : 16|8@1- (1,0) [-128|127] "'C" Vector__XXX
 SG_ TEM_8_therm_131_value m131 : 16|8@1- (1,0) [-128|127] "'C" Vector__XXX
 SG_ TEM_8_therm_132_value m132 : 16|8@1- (1,0) [-128|127] "'C" Vector__XXX
 SG_ TEM_8_therm_133_value m133 : 16|8@1- (1,0) [-128|127] "'C" Vector__XXX
 SG_ TEM_8_therm_134_value m134 : 16|8@1- (1,0) [-128|127] "'C" Vector__XXX
 SG_ TEM_8_therm_135_value m135 : 16|8@1- (1,0) [-128|127] "'C" Vector__XXX
 SG_ TEM_8_therm_136_value m136 : 16|8@1- (1,0) [-128|127] "'C" Vector__XXX
 SG_ TEM_8_therm_137_value m137 : 16|8@1- (1,0) [-128|127] "'C" Vector__XXX
 SG_ TEM_8_therm_138_value m138 : 16|8@1- (1,0) [-128|127] "'C" Vector__XXX
 SG_ TEM_8_therm_139_value m139 : 16|8@1- (1,0) [-128|127] "'C" Vector__XXX
 SG_ TEM_8_therm_140_value m140 : 16|8@1- (1,0) [-128|127] "'C" Vector__XXX
 SG_ TEM_8_therm_141_value m141 : 16|8@1- (1,0) [-128|127] "'C" Vector__XXX
 SG_ TEM_8_therm_142_value m142 : 16|8@1- (1,0) [-128|127] "'C" Vector__XXX
 SG_ TEM_8_therm_143_value m143 : 16|8@1- (1,0) [-128|127] "'C" Vector__XXX
 SG_ TEM_8_therm_144_value m144 : 16|8@1- (1,0) [-128|127] "'C" Vector__XXX
 SG_ TEM_8_therm_145_value m145 : 16|8@1- (1,0) [-128|127] "'C" Vector__XXX
 SG_ TEM_8_therm_146_value m146 : 16|8@1- (1,0) [-128|127] "'C" Vector__XXX
 SG_ TEM_8_therm_147_value m147 : 16|8@1- (1,0) [-128|127] "'C" Vector__XXX
 SG_ TEM_8_therm_148_value m148 : 16|8@1- (1,0) [-128|127] "'C" Vector__XXX
 SG_ TEM_8_therm_149_value m149 : 16|8@1- (1,0) [-128|127] "'C" Vector__XXX
 SG_ TEM_8_therm_150_value m150 : 16|8@1- (1,0) [-128|127] "'C" Vector__XXX
 SG_ TEM_8_therm_151_value m151 : 16|8@1- (1,0) [-128|127] "'C" Vector__XXX
 SG_ TEM_8_therm_count : 24|8@1+ (1,0) [0|255] "" Vector__XXX
 SG_ TEM_8_lowest_temp : 32|8@1- (1,0) [-128|127] "'C" Vector__XXX
 SG_ TEM_8_Highest_temp : 40|8@1- (1,0) [-128|127] "'C" Vector__XXX
 SG_ TEM_8_highest_therm_ID : 48|8@1+ (1,0) [0|255] "" Vector__XXX
 SG_ TEM_8_Lowest_therm_ID : 56|8@1+ (1,0) [0|255] "" Vector__XXX

BO_ 2553934729 TEM_9_BMS_BROADCAST: 8 Vector__XXX
 SG_ TEM_9_therm_m_num : 0|8@1+ (1,0) [0|255] "" Vector__XXX
 SG_ TEM_9_lowst_temp : 8|8@1- (1,0) [-128|127] "'C" Vector__XXX
 SG_ TEM_9_highest_temp : 16|8@1- (1,0) [-128|127] "'C" Vector__XXX
 SG_ TEM_9_avg_temp : 24|8@1- (1,0) [-128|127] "'C" Vector__XXX
 SG_ TEM_9_therm_count : 32|8@1+ (1,0) [0|255] "" Vector__XXX
 SG_ TEM_9_highest_therm_ID : 40|8@1+ (1,0) [0|255] "" Vector__XXX
 SG_ TEM_9_lowest_therm_ID : 48|8@1+ (1,0) [0|255] "" Vector__XXX
 SG_ TEM_9_checksum : 56|8@1+ (1,0) [0|255] "" Vector__XXX

BO_ 2553869193 TEM_9_GENERAL_BROADCAST: 8 Vector__XXX
 SG_ TEM_9_relative_therm_ID M : 15|8@0+ (1,0) [0|255] "" Vector__XXX
 SG_ TEM_9_therm_208_value m208 : 16|8@1- (1,0) [-128|127] "'C" Vector__XXX
 SG_ TEM_9_therm_209_value m209 : 16|8@1- (1,0) [-128|127] "'C" Vector__XXX
 SG_ TEM_9_therm_210_value m210 : 16|8@1- (1,0) [-128|127] "'C" Vector__XXX
 SG_ TEM_9_therm_211_value m211 : 16|8@1- (1,0) [-128|127] "'C" Vector__XXX
 SG_ TEM_9_therm_212_value m212 : 16|8@1- (1,0) [-128|127] "'C" Vector__XXX
 SG_ TEM_9_therm_213_value m213 : 16|8@1- (1,0) [-128|127] "'C" Vector__XXX
 SG_ TEM_9_therm_214_value m214 : 16|8@1- (1,0) [-128|127] "'C" Vector__XXX
 SG_ TEM_9_therm_215_value m215 : 16|8@1- (1,0) [-128|127] "'C" Vector__XXX
 SG_ TEM_9_therm_216_value m216 : 16|8@1- (1,0) [-128|127] "'C" Vector__XXX
 SG_ TEM_9_therm_217_value m217 : 16|8@1- (1,0) [-128|127] "'C" Vector__XXX
 SG_ TEM_9_therm_218_value m218 : 16|8@1- (1,0) [-128|127] "'C" Vector__XXX
 SG_ TEM_9_therm_219_value m219 : 16|8@1- (1,0) [-128|127] "'C" Vector__XXX
 SG_ TEM_9_therm_220_value m220 : 16|8@1- (1,0) [-128|127] "'C" Vector__XXX
 SG_ TEM_9_therm_221_value m221 : 16|8@1- (1,0) [-128|127] "'C" Vector__XXX
 SG_ TEM_9_therm_222_value m222 : 16|8@1- (1,0) [-128|127] "'C" Vector__XXX
 SG_ TEM_9_therm_223_value m223 : 16|8@1- (1,0) [-128|127] "'C" Vector__XXX
 SG_ TEM_9_therm_224_value m224 : 16|8@1- (1,0) [-128|127] "'C" Vector__XXX
 SG_ TEM_9_therm_225_value m225 : 16|8@1- (1,0) [-128|127] "'C" Vector__XXX
 SG_ TEM_9_therm_226_value m226 : 16|8@1- (1,0) [-128|127] "'C" Vector__XXX
 SG_ TEM_9_therm_227_value m227 : 16|8@1- (1,0) [-128|127] "'C" Vector__XXX
 SG_ TEM_9_therm_228_value m228 : 16|8@1- (1,0) [-128|127] "'C" Vector__XXX
 SG_ TEM_9_therm_229_value m229 : 16|8@1- (1,0) [-128|127] "'C" Vector__XXX
 SG_ TEM_9_therm_230_value m230 : 16|8@1- (1,0) [-128|127] "'C" Vector__XXX
 SG_ TEM_9_therm_231_value m231 : 16|8@1- (1,0) [-128|127] "'C" Vector__XXX
 SG_ TEM_9_therm_count : 24|8@1+ (1,0) [0|255] "" Vector__XXX
 SG_ TEM_9_lowest_temp : 32|8@1- (1,0) [-128|127] "'C" Vector__XXX
 SG_ TEM_9_Highest_temp : 40|8@1- (1,0) [-128|127] "'C" Vector__XXX
 SG_ TEM_9_highest_therm_ID : 48|8@1+ (1,0) [0|255] "" Vector__XXX
 SG_ TEM_9_Lowest_therm_ID : 56|8@1+ (1,0) [0|255] "" Vector__XXX

CM_ BU_ PDM "Motec Power Distribution Module";
CM_ BU_ INV "The Cascadia Motion inverter";
CM_ BU_ U2C "Delphi DC/DC Converter";
CM_ BU_ VCU "The system vehicle control unit";
CM_ BU_ BMS "BMS Master";
CM_ SG_ 173 PM100_Iq_Command "The commanded Q-axis current";
CM_ SG_ 173 PM100_Id_Command "The commanded D-axis current";
CM_ SG_ 173 PM100_Flux_Weakening_Output "This is the current output of the flux regulator.";
CM_ SG_ 173 PM100_Modulation_Index "This is the modulation index. The scale factor is x100. To get the actual modulation index divide the value by 100.";
CM_ SG_ 172 PM100_Power_On_Timer "Updated every 3 msec. This will roll over in approximately 150 days!";
CM_ SG_ 172 PM100_Torque_Feedback "Estimated motor torque feedback";
CM_ SG_ 172 PM100_Commanded_Torque "The commanded Torque";
CM_ BO_ 194 "The inverter response to each Parameter message that is received.";
CM_ SG_ 194 PM100_Write_Success "0=Write failure, 1=Success";
CM_ SG_ 194 PM100_Data_Response "All EEPROM data is 16 bits and is contained in bytes 4 and 5. Bytes 6 and 7 should be ignored.";
CM_ SG_ 194 PM100_Parameter_Addr_Response "Valid EEPROM Parameter CAN addresses are between 100 and 499.";
CM_ BO_ 193 "Parameter Message sent as needed by VCU to request info, change EEPROM, or command a function.";
CM_ SG_ 193 PM100_Data_Command "All EEPROM data is 16 bits and is contained in bytes 4 and 5.";
CM_ SG_ 193 PM100_Read_Write_Cmd "0=Read, 1=Write";
CM_ SG_ 193 PM100_Parameter_Address_Cmd "Valid EEPROM Parameter CAN addresses are between 100 and 499.";
CM_ BO_ 192 "The command message is used to transmit data to the controller. This message is sent from a user supplied external controller to the PMxxx controller.";
CM_ SG_ 192 PM100_Inverter_Enable "0=Inverter OFF, 1 = Inverter ON";
CM_ SG_ 192 PM100_Direction_Command "0=CW, 1=CCW as veiwed from the shaft end of the motor";
CM_ SG_ 192 PM100_Speed_Command "Speed commandused when in speed mode";
CM_ SG_ 192 PM100_Torque_Command "Torque command when in torque mode";
CM_ SG_ 192 PM100_Inverter_Discharge "0=Discharge Disable,
=Discharge Enable";
CM_ SG_ 192 PM100_Torque_Limit_Command "Torque Limit, set to 0 to keep default";
CM_ SG_ 192 PM100_Speed_Mode_Enable "0 = No change to mode, 1 = change to speed mode from torque mode";
CM_ SG_ 192 PM100_Rolling_Counter "Rolling Counter command";
CM_ SG_ 171 PM100_Run_Fault_Hi "Each bit represents a fault. Please refer to PM100 Users Manual for details.";
CM_ SG_ 171 PM100_Post_Fault_Hi "Each bit represents a fault. Please refer to PM100 Users Manual for details.";
CM_ SG_ 171 PM100_Run_Fault_Lo "Each bit represents a fault. Please refer to PM100 Users Manual for details.";
CM_ SG_ 171 PM100_Post_Fault_Lo "Each bit represents a fault. Please refer to PM100 Users Manual for details.";
CM_ SG_ 170 PM100_Direction_Command "1 = Forward
0 = 'Reverse' if inverter enabled  & 'Stopped' if inverter is disabled";
CM_ SG_ 170 PM100_Inverter_Enable_State "0=Inverter Disabled, 
1=Inverter Enabled";
CM_ SG_ 170 PM100_Relay_3_Status "0=OFF, 1=ON";
CM_ SG_ 170 PM100_Relay_4_Status "0=OFF, 1=ON";
CM_ SG_ 170 PM100_Relay_2_Status "0=OFF, 1=ON";
CM_ SG_ 170 PM100_Inverter_Run_Mode "0=Torque Mode, 1=Speed Mode";
CM_ SG_ 170 PM100_Inverter_Command_Mode "0=CAN mode, 1=VSM mode";
CM_ SG_ 170 PM100_Relay_1_Status "0=OFF, 1=ON";
CM_ SG_ 170 PM100_Inverter_State "Different states for the inverter state machine";
CM_ SG_ 170 PM100_VSM_State "Different states for the vehicle state machine";
CM_ SG_ 170 PM100_Inverter_Enable_Lockout "0=Lockout Disabled, 1=Lockout Enabled";
CM_ SG_ 170 PM100_Inverter_Discharge_State "0 = Disabled, 1 = Enabled, 2 = Speed Check, 3 = Active, 4 = Complete";
CM_ SG_ 170 PM100_Relay_5_Status "0=OFF, 1=ON";
CM_ SG_ 170 PM100_Relay_6_Status "0=OFF, 1=ON";
CM_ SG_ 170 PM100_BMS_Active "0 = BMS Not Active, 1 = BMS Active";
CM_ SG_ 170 PM100_BMS_Torque_Limiting "0 = Not Limiting, 1 = Limiting";
CM_ SG_ 170 PM100_Max_Speed_Limiting "0 = Not Limiting, 1 = torque limiting due to maximum speed";
CM_ SG_ 170 PM100_Low_Speed_Limiting "0 = Not Limiting, 1 = Current limiting due to low motor speed";
CM_ SG_ 170 PM100_Rolling_Counter "The current rolling counter value.";
CM_ SG_ 170 PM100_PWM_Frequency "The inverter PWM frequency";
CM_ SG_ 170 PM100_Start_Mode_Active "If in Key Switch Mode 1 then indicates status of Start input being applied.  0 = not active, 1 = active";
CM_ SG_ 169 PM100_Reference_Voltage_12_0 "12V Input Voltage";
CM_ SG_ 169 PM100_Reference_Voltage_5_0 "Transducer voltage";
CM_ SG_ 169 PM100_Reference_Voltage_2_5 "Internal reference voltage";
CM_ SG_ 169 PM100_Reference_Voltage_1_5 "Internal reference voltage";
CM_ SG_ 168 PM100_Iq "The measured Iq current";
CM_ SG_ 168 PM100_Id "The measured Id current";
CM_ SG_ 168 PM100_Flux_Feedback "The estimated flux";
CM_ SG_ 168 PM100_Flux_Command "The commanded flux";
CM_ SG_ 167 PM100_VBC_Vq_Voltage "Measured value of the voltage between Phase B and Phase C";
CM_ SG_ 167 PM100_VAB_Vd_Voltage "Measured value of the voltage betwen phase A and Phase B";
CM_ SG_ 167 PM100_Output_Voltage "The calculated value of the output voltage, in peak line-neutral volts";
CM_ SG_ 167 PM100_DC_Bus_Voltage "The actual measured value of the DC bus voltage";
CM_ SG_ 166 PM100_DC_Bus_Current "The Calculated DC Bus Current";
CM_ SG_ 166 PM100_Phase_C_Current "The measured value of Phase C current";
CM_ SG_ 166 PM100_Phase_B_Current "The measured value of Phase B current";
CM_ SG_ 166 PM100_Phase_A_Current "The measured value of Phase A current";
CM_ SG_ 165 PM100_Delta_Resolver_Filtered "Used in calibration of resolver angle adjustment.";
CM_ SG_ 165 PM100_Electrical_Output_Freq "The actual electrical frequency of the inverter";
CM_ SG_ 165 PM100_Motor_Speed "The measured speed of the motor";
CM_ SG_ 165 PM100_Motor_Angle_Electrical "The Electrical Angle of the motor as read by the encoder or resolver";
CM_ SG_ 164 PM100_Digital_Input_5 "Status of Digital Input #5";
CM_ SG_ 164 PM100_Digital_Input_4 "Status of Digital Input #4";
CM_ SG_ 164 PM100_Digital_Input_3 "Status of Digital Input #3";
CM_ SG_ 164 PM100_Digital_Input_2 "Status of Digital Input #2";
CM_ SG_ 164 PM100_Digital_Input_1 "Status of Digital Input #1";
CM_ SG_ 164 PM100_Digital_Input_6 "Status of Digital Input #6";
CM_ SG_ 164 PM100_Digital_Input_7 "Status of Digital Input #7";
CM_ SG_ 164 PM100_Digital_Input_8 "Status of Digital Input #8";
CM_ SG_ 163 PM100_Analog_Input_4 "Voltage on Analog Input #4";
CM_ SG_ 163 PM100_Analog_Input_3 "Voltage on Analog Input #3";
CM_ SG_ 163 PM100_Analog_Input_2 "Voltage on Analog Input #2";
CM_ SG_ 163 PM100_Analog_Input_1 "Voltage on Analog Input #1";
CM_ SG_ 163 PM100_Analog_Input_5 "Voltage on Analog Input #5";
CM_ SG_ 163 PM100_Analog_Input_6 "Voltage on Analog Input #6";
CM_ SG_ 162 PM100_Torque_Shudder "Shudder compensation value of torque";
CM_ SG_ 162 PM100_Motor_Temperature "Motor Temperature Sensor";
CM_ SG_ 162 PM100_RTD5_Temperature "RTD 5 (PT1000) Temperature (Gen 2 only)";
CM_ SG_ 162 PM100_RTD4_Temperature "RTD 4 (PT1000) Temperature (Gen 2 only)";
CM_ SG_ 161 PM100_RTD3_Temperature "RTD input 3 (PT1000) Temperature (Gen 2 only)";
CM_ SG_ 161 PM100_RTD2_Temperature "RTD input 2 (PT1000) Temperature";
CM_ SG_ 161 PM100_RTD1_Temperature "RTD input 1 (PT1000) Temperature";
CM_ SG_ 161 PM100_Control_Board_Temperature "Control Board Temperature";
CM_ SG_ 160 PM100_Gate_Driver_Board "Gate Driver Board Temperature";
CM_ SG_ 160 PM100_Module_C "IGBT Module C Temperature";
CM_ SG_ 160 PM100_Module_B "IGBT Module B Temperature";
CM_ SG_ 160 PM100_Module_A "IGBT Module A Temperature";
CM_ BO_ 471 "Enable message sent to Delphi DC/DC converter.";
CM_ BO_ 469 "Response from Delphi DC/DC converter.";
CM_ BO_ 176 "To enable fast message set CAN ACTIVE MSGS HI WORD to 0xFFFE.  Setting to default value of 0xFFFF will disable the fast message.";
CM_ SG_ 176 PM100_Fast_Torque_Command "The commanded torque";
CM_ SG_ 176 PM100_Fast_Torque_Feedback "The estimated torque";
CM_ SG_ 176 PM100_Fast_Motor_Speed "Motor speed";
CM_ SG_ 176 PM100_Fast_DC_Bus_Voltage "DC Bus Voltage";
CM_ BO_ 512 "This ID Transmits at 8 ms.";
CM_ BO_ 513 "This ID Transmits at 8 ms.";
CM_ BO_ 514 "This ID Transmits at 8 ms.Message sent by BMS for inverter DC current limiting.";
CM_ BO_ 515 "This ID Transmits at 8 ms.";
CM_ BO_ 2550589428 "This ID Transmits at 808 ms.";
CM_ BO_ 2550588916 "This ID Transmits at 808 ms.";
CM_ BO_ 2550589940 "This ID Transmits at 808 ms.";
BA_DEF_ BO_  "GenMsgCycleTime" INT 0 100000;
BA_DEF_  "BusType" STRING ;
BA_DEF_ SG_  "SystemSignalLongSymbol" STRING ;
BA_DEF_DEF_  "GenMsgCycleTime" 0;
BA_DEF_DEF_  "BusType" "CAN";
BA_DEF_DEF_  "SystemSignalLongSymbol" "";
BA_ "GenMsgCycleTime" BO_ 172 10;
BA_ "GenMsgCycleTime" BO_ 192 5;
BA_ "GenMsgCycleTime" BO_ 171 100;
BA_ "GenMsgCycleTime" BO_ 170 100;
BA_ "GenMsgCycleTime" BO_ 169 100;
BA_ "GenMsgCycleTime" BO_ 168 10;
BA_ "GenMsgCycleTime" BO_ 167 10;
BA_ "GenMsgCycleTime" BO_ 166 10;
BA_ "GenMsgCycleTime" BO_ 165 10;
BA_ "GenMsgCycleTime" BO_ 164 10;
BA_ "GenMsgCycleTime" BO_ 163 10;
BA_ "GenMsgCycleTime" BO_ 162 100;
BA_ "GenMsgCycleTime" BO_ 161 100;
BA_ "GenMsgCycleTime" BO_ 160 100;
BA_ "GenMsgCycleTime" BO_ 176 3;
BA_ "GenMsgCycleTime" BO_ 2018 1000;
BA_ "GenMsgCycleTime" BO_ 2019 1000;
BA_ "SystemSignalLongSymbol" SG_ 2550589428 DTC_P0A08_Charger_Safety_Relay_F "DTC_P0A08_Charger_Safety_Relay_Fault";
BA_ "SystemSignalLongSymbol" SG_ 2550588916 DTC_P0A08_Charger_Safety_Re_0000 "DTC_P0A08_Charger_Safety_Relay_Fault";
BA_ "SystemSignalLongSymbol" SG_ 2550589940 DTC_P0A08_Charger_Safety_Re_0001 "DTC_P0A08_Charger_Safety_Relay_Fault";
BA_ "SystemSignalLongSymbol" SG_ 2018 CAN_T_Rptr_CAN1_to_CAN2_QueueDep "CAN_T_Rptr_CAN1_to_CAN2_QueueDepth";
BA_ "SystemSignalLongSymbol" SG_ 2018 CAN_T_Rptr_CAN2_to_CAN1_QueueDep "CAN_T_Rptr_CAN2_to_CAN1_QueueDepth";
BA_ "SystemSignalLongSymbol" SG_ 2019 CAN_Isolator_CAN1_to_CAN2_QueueD "CAN_Isolator_CAN1_to_CAN2_QueueDepth";
BA_ "SystemSignalLongSymbol" SG_ 2019 CAN_Isolator_CAN2_to_CAN1_QueueD "CAN_Isolator_CAN2_to_CAN1_QueueDepth";
VAL_ 192 PM100_Inverter_Enable 0 "Turn the inverter OFF" 1 "Turn the Inverter ON" ;
VAL_ 192 PM100_Direction_Command 0 "CW" 1 "CCW" ;
VAL_ 192 PM100_Inverter_Discharge 0 "Discharge Disable" 1 "Discharge Enable (if EEPROM parameter is set)" ;
VAL_ 170 PM100_Inverter_State 0 "Power up" 1 "Stop" 2 "Open Loop" 3 "Closed Loop" 4 "Internal State" 5 "Internal State" 6 "Internal State" 7 "Internal State" 8 "Idle Run" 9 "Idle Stop" 10 "Internal State" 11 "Intern State" 12 "Internal State" ;
VAL_ 170 PM100_VSM_State 0 "VSM Start State" 1 "Pre-Charge Init state" 2 "pre-charge active state" 3 "pre-charge complete state" 4 "VSM wait state" 5 "VSM ready state" 6 "Motor Running State" 7 "blink fault code state" 14 "Shutdown state for Key Switch Mode 1" 15 "Reset the inverter" ;
VAL_ 257 VCU_Requested_Mode 1 "Endurance" 2 "Max" 3 "Torque_Ctrl" 4 "Crawl" 5 "Reverse" 6 "Remote_Ctrl" 7 "Undefined" 8 "Undefined" 9 "Undefined" 10 "Inverter_Prog" ;
VAL_ 257 VCU_Current_Mode 1 "Endurance" 2 "Max" 3 "Torque_Ctrl" 4 "Crawl" 5 "Reverse" 6 "Remote_Ctrl" 7 "Undefined" 8 "Undefined" 9 "Undefined" 10 "Inverter_Prog" ;
VAL_ 257 VCU_CTRL_State 0 "TS Button Wait" 1 "Wait Neg AIR" 2 "Precharge Wait" 3 "R2D Wait" 4 "TS On" 5 "R2D Off" 6 "R2D Off Wait" 7 "TS Activation Failure" 8 "TS Run Fault" 9 "Spin" 10 "APPS SCS Fault" 11 "APPS BPS Fault" 12 "Sim Wait TS Off" 13 "Sim Wait TS On" 14 "Sim Wait R2D Off" 15 "Sim Wait R2D On" ;
